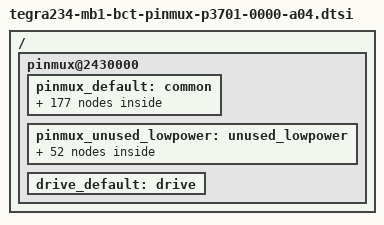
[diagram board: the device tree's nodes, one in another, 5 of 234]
/*This dtsi file was generated by jetson_agx_orin.xlsm Revision: 2 */
/*
 * SPDX-FileCopyrightText: Copyright (c) 2022-2024 NVIDIA CORPORATION & AFFILIATES. All rights reserved.
 * SPDX-License-Identifier: BSD-3-Clause
 *
 * Redistribution and use in source and binary forms, with or without
 * modification, are permitted provided that the following conditions are met:
 *
 * 1. Redistributions of source code must retain the above copyright notice, this
 * list of conditions and the following disclaimer.
 *
 * 2. Redistributions in binary form must reproduce the above copyright notice,
 * this list of conditions and the following disclaimer in the documentation
 * and/or other materials provided with the distribution.
 *
 * 3. Neither the name of the copyright holder nor the names of its
 * contributors may be used to endorse or promote products derived from
 * this software without specific prior written permission.
 *
 * THIS SOFTWARE IS PROVIDED BY THE COPYRIGHT HOLDERS AND CONTRIBUTORS 'AS IS'
 * AND ANY EXPRESS OR IMPLIED WARRANTIES, INCLUDING, BUT NOT LIMITED TO, THE
 * IMPLIED WARRANTIES OF MERCHANTABILITY AND FITNESS FOR A PARTICULAR PURPOSE ARE
 * DISCLAIMED. IN NO EVENT SHALL THE COPYRIGHT HOLDER OR CONTRIBUTORS BE LIABLE
 * FOR ANY DIRECT, INDIRECT, INCIDENTAL, SPECIAL, EXEMPLARY, OR CONSEQUENTIAL
 * DAMAGES (INCLUDING, BUT NOT LIMITED TO, PROCUREMENT OF SUBSTITUTE GOODS OR
 * SERVICES; LOSS OF USE, DATA, OR PROFITS; OR BUSINESS INTERRUPTION) HOWEVER
 * CAUSED AND ON ANY THEORY OF LIABILITY, WHETHER IN CONTRACT, STRICT LIABILITY,
 * OR TORT (INCLUDING NEGLIGENCE OR OTHERWISE) ARISING IN ANY WAY OUT OF THE USE
 * OF THIS SOFTWARE, EVEN IF ADVISED OF THE POSSIBILITY OF SUCH DAMAGE.
 */

/dts-v1/;
#include "pinctrl-tegra.h"
#include "tegra234-mb1-bct-gpio-p3701-0000-a04.dtsi"

/ {
	pinmux@2430000 {
		pinctrl-names = "default", "drive", "unused";
		pinctrl-0 = <&pinmux_default>;
		pinctrl-1 = <&drive_default>;
		pinctrl-2 = <&pinmux_unused_lowpower>;

		pinmux_default: common {
			/* SFIO Pin Configuration */
			shutdown_n {
				nvidia,pins = "shutdown_n";
				nvidia,function = "shutdown";
				nvidia,pull = <TEGRA_PIN_PULL_NONE>;
				nvidia,tristate = <TEGRA_PIN_DISABLE>;
				nvidia,enable-input = <TEGRA_PIN_DISABLE>;
				nvidia,io-high-voltage = <TEGRA_PIN_DISABLE>;
				nvidia,lpdr = <TEGRA_PIN_DISABLE>;
			};

			batt_oc_pee3 {
				nvidia,pins = "batt_oc_pee3";
				nvidia,function = "soc";
				nvidia,pull = <TEGRA_PIN_PULL_NONE>;
				nvidia,tristate = <TEGRA_PIN_ENABLE>;
				nvidia,enable-input = <TEGRA_PIN_ENABLE>;
				nvidia,io-high-voltage = <TEGRA_PIN_DISABLE>;
				nvidia,lpdr = <TEGRA_PIN_DISABLE>;
			};

			hdmi_cec_pgg0 {
				nvidia,pins = "hdmi_cec_pgg0";
				nvidia,function = "hdmi";
				nvidia,pull = <TEGRA_PIN_PULL_NONE>;
				nvidia,tristate = <TEGRA_PIN_DISABLE>;
				nvidia,enable-input = <TEGRA_PIN_ENABLE>;
				nvidia,io-high-voltage = <TEGRA_PIN_ENABLE>;
				nvidia,lpdr = <TEGRA_PIN_DISABLE>;
			};

			touch_clk_pcc4 {
				nvidia,pins = "touch_clk_pcc4";
				nvidia,function = "gp";
				nvidia,pull = <TEGRA_PIN_PULL_NONE>;
				nvidia,tristate = <TEGRA_PIN_ENABLE>;
				nvidia,enable-input = <TEGRA_PIN_DISABLE>;
				nvidia,io-high-voltage = <TEGRA_PIN_ENABLE>;
				nvidia,lpdr = <TEGRA_PIN_DISABLE>;
			};

			uart3_tx_pcc5 {
				nvidia,pins = "uart3_tx_pcc5";
				nvidia,function = "uartc";
				nvidia,pull = <TEGRA_PIN_PULL_NONE>;
				nvidia,tristate = <TEGRA_PIN_DISABLE>;
				nvidia,enable-input = <TEGRA_PIN_DISABLE>;
				nvidia,io-high-voltage = <TEGRA_PIN_DISABLE>;
				nvidia,lpdr = <TEGRA_PIN_DISABLE>;
			};

			uart3_rx_pcc6 {
				nvidia,pins = "uart3_rx_pcc6";
				nvidia,function = "uartc";
				nvidia,pull = <TEGRA_PIN_PULL_NONE>;
				nvidia,tristate = <TEGRA_PIN_ENABLE>;
				nvidia,enable-input = <TEGRA_PIN_ENABLE>;
				nvidia,io-high-voltage = <TEGRA_PIN_DISABLE>;
				nvidia,lpdr = <TEGRA_PIN_DISABLE>;
			};

			gen2_i2c_scl_pcc7 {
				nvidia,pins = "gen2_i2c_scl_pcc7";
				nvidia,function = "i2c2";
				nvidia,pull = <TEGRA_PIN_PULL_NONE>;
				nvidia,tristate = <TEGRA_PIN_DISABLE>;
				nvidia,enable-input = <TEGRA_PIN_ENABLE>;
				nvidia,io-high-voltage = <TEGRA_PIN_ENABLE>;
				nvidia,lpdr = <TEGRA_PIN_DISABLE>;
			};

			gen2_i2c_sda_pdd0 {
				nvidia,pins = "gen2_i2c_sda_pdd0";
				nvidia,function = "i2c2";
				nvidia,pull = <TEGRA_PIN_PULL_NONE>;
				nvidia,tristate = <TEGRA_PIN_DISABLE>;
				nvidia,enable-input = <TEGRA_PIN_ENABLE>;
				nvidia,io-high-voltage = <TEGRA_PIN_ENABLE>;
				nvidia,lpdr = <TEGRA_PIN_DISABLE>;
			};

			gen8_i2c_scl_pdd1 {
				nvidia,pins = "gen8_i2c_scl_pdd1";
				nvidia,function = "i2c8";
				nvidia,pull = <TEGRA_PIN_PULL_NONE>;
				nvidia,tristate = <TEGRA_PIN_DISABLE>;
				nvidia,enable-input = <TEGRA_PIN_ENABLE>;
				nvidia,io-high-voltage = <TEGRA_PIN_ENABLE>;
				nvidia,lpdr = <TEGRA_PIN_DISABLE>;
			};

			gen8_i2c_sda_pdd2 {
				nvidia,pins = "gen8_i2c_sda_pdd2";
				nvidia,function = "i2c8";
				nvidia,pull = <TEGRA_PIN_PULL_NONE>;
				nvidia,tristate = <TEGRA_PIN_DISABLE>;
				nvidia,enable-input = <TEGRA_PIN_ENABLE>;
				nvidia,io-high-voltage = <TEGRA_PIN_ENABLE>;
				nvidia,lpdr = <TEGRA_PIN_DISABLE>;
			};

			can0_stb_paa4 {
				nvidia,pins = "can0_stb_paa4";
				nvidia,function = "tsc_edge_out2";
				nvidia,pull = <TEGRA_PIN_PULL_DOWN>;
				nvidia,tristate = <TEGRA_PIN_DISABLE>;
				nvidia,enable-input = <TEGRA_PIN_DISABLE>;
			};

			can0_err_paa7 {
				nvidia,pins = "can0_err_paa7";
				nvidia,function = "tsc_edge_out3";
				nvidia,pull = <TEGRA_PIN_PULL_DOWN>;
				nvidia,tristate = <TEGRA_PIN_DISABLE>;
				nvidia,enable-input = <TEGRA_PIN_DISABLE>;
			};

			soc_gpio50_pbb2 {
				nvidia,pins = "soc_gpio50_pbb2";
				nvidia,function = "tsc_edge_out0";
				nvidia,pull = <TEGRA_PIN_PULL_DOWN>;
				nvidia,tristate = <TEGRA_PIN_DISABLE>;
				nvidia,enable-input = <TEGRA_PIN_DISABLE>;
			};

			gp_pwm2_px2 {
				nvidia,pins = "gp_pwm2_px2";
				nvidia,function = "gp";
				nvidia,pull = <TEGRA_PIN_PULL_NONE>;
				nvidia,tristate = <TEGRA_PIN_ENABLE>;
				nvidia,enable-input = <TEGRA_PIN_DISABLE>;
				nvidia,io-high-voltage = <TEGRA_PIN_ENABLE>;
				nvidia,lpdr = <TEGRA_PIN_DISABLE>;
			};

			gp_pwm3_px3 {
				nvidia,pins = "gp_pwm3_px3";
				nvidia,function = "gp";
				nvidia,pull = <TEGRA_PIN_PULL_NONE>;
				nvidia,tristate = <TEGRA_PIN_DISABLE>;
				nvidia,enable-input = <TEGRA_PIN_DISABLE>;
				nvidia,io-high-voltage = <TEGRA_PIN_DISABLE>;
				nvidia,lpdr = <TEGRA_PIN_DISABLE>;
			};

			uart2_tx_px4 {
				nvidia,pins = "uart2_tx_px4";
				nvidia,function = "uartb";
				nvidia,pull = <TEGRA_PIN_PULL_NONE>;
				nvidia,tristate = <TEGRA_PIN_DISABLE>;
				nvidia,enable-input = <TEGRA_PIN_DISABLE>;
				nvidia,io-high-voltage = <TEGRA_PIN_DISABLE>;
				nvidia,lpdr = <TEGRA_PIN_DISABLE>;
			};

			uart2_rx_px5 {
				nvidia,pins = "uart2_rx_px5";
				nvidia,function = "uartb";
				nvidia,pull = <TEGRA_PIN_PULL_NONE>;
				nvidia,tristate = <TEGRA_PIN_ENABLE>;
				nvidia,enable-input = <TEGRA_PIN_ENABLE>;
				nvidia,io-high-voltage = <TEGRA_PIN_DISABLE>;
				nvidia,lpdr = <TEGRA_PIN_DISABLE>;
			};

			uart2_rts_px6 {
				nvidia,pins = "uart2_rts_px6";
				nvidia,function = "uartb";
				nvidia,pull = <TEGRA_PIN_PULL_NONE>;
				nvidia,tristate = <TEGRA_PIN_DISABLE>;
				nvidia,enable-input = <TEGRA_PIN_DISABLE>;
				nvidia,lpdr = <TEGRA_PIN_DISABLE>;
			};

			uart2_cts_px7 {
				nvidia,pins = "uart2_cts_px7";
				nvidia,function = "uartb";
				nvidia,pull = <TEGRA_PIN_PULL_NONE>;
				nvidia,tristate = <TEGRA_PIN_ENABLE>;
				nvidia,enable-input = <TEGRA_PIN_ENABLE>;
				nvidia,lpdr = <TEGRA_PIN_DISABLE>;
			};

			uart5_tx_py5 {
				nvidia,pins = "uart5_tx_py5";
				nvidia,function = "uarti";
				nvidia,pull = <TEGRA_PIN_PULL_NONE>;
				nvidia,tristate = <TEGRA_PIN_DISABLE>;
				nvidia,enable-input = <TEGRA_PIN_DISABLE>;
				nvidia,lpdr = <TEGRA_PIN_DISABLE>;
			};

			uart5_rx_py6 {
				nvidia,pins = "uart5_rx_py6";
				nvidia,function = "uarti";
				nvidia,pull = <TEGRA_PIN_PULL_NONE>;
				nvidia,tristate = <TEGRA_PIN_ENABLE>;
				nvidia,enable-input = <TEGRA_PIN_ENABLE>;
				nvidia,lpdr = <TEGRA_PIN_DISABLE>;
			};

			extperiph1_clk_pp0 {
				nvidia,pins = "extperiph1_clk_pp0";
				nvidia,function = "extperiph1";
				nvidia,pull = <TEGRA_PIN_PULL_NONE>;
				nvidia,tristate = <TEGRA_PIN_DISABLE>;
				nvidia,enable-input = <TEGRA_PIN_DISABLE>;
				nvidia,lpdr = <TEGRA_PIN_DISABLE>;
			};

			extperiph2_clk_pp1 {
				nvidia,pins = "extperiph2_clk_pp1";
				nvidia,function = "extperiph2";
				nvidia,pull = <TEGRA_PIN_PULL_NONE>;
				nvidia,tristate = <TEGRA_PIN_DISABLE>;
				nvidia,enable-input = <TEGRA_PIN_DISABLE>;
				nvidia,lpdr = <TEGRA_PIN_DISABLE>;
			};

			cam_i2c_scl_pp2 {
				nvidia,pins = "cam_i2c_scl_pp2";
				nvidia,function = "i2c3";
				nvidia,pull = <TEGRA_PIN_PULL_NONE>;
				nvidia,tristate = <TEGRA_PIN_DISABLE>;
				nvidia,enable-input = <TEGRA_PIN_ENABLE>;
				nvidia,io-high-voltage = <TEGRA_PIN_ENABLE>;
				nvidia,lpdr = <TEGRA_PIN_DISABLE>;
			};

			cam_i2c_sda_pp3 {
				nvidia,pins = "cam_i2c_sda_pp3";
				nvidia,function = "i2c3";
				nvidia,pull = <TEGRA_PIN_PULL_NONE>;
				nvidia,tristate = <TEGRA_PIN_DISABLE>;
				nvidia,enable-input = <TEGRA_PIN_ENABLE>;
				nvidia,io-high-voltage = <TEGRA_PIN_ENABLE>;
				nvidia,lpdr = <TEGRA_PIN_DISABLE>;
			};

			soc_gpio24_pp5 {
				nvidia,pins = "soc_gpio24_pp5";
				nvidia,function = "soc";
				nvidia,pull = <TEGRA_PIN_PULL_NONE>;
				nvidia,tristate = <TEGRA_PIN_ENABLE>;
				nvidia,enable-input = <TEGRA_PIN_ENABLE>;
				nvidia,io-high-voltage = <TEGRA_PIN_DISABLE>;
				nvidia,lpdr = <TEGRA_PIN_DISABLE>;
			};

			pwr_i2c_scl_pp7 {
				nvidia,pins = "pwr_i2c_scl_pp7";
				nvidia,function = "i2c5";
				nvidia,pull = <TEGRA_PIN_PULL_NONE>;
				nvidia,tristate = <TEGRA_PIN_DISABLE>;
				nvidia,enable-input = <TEGRA_PIN_ENABLE>;
				nvidia,io-high-voltage = <TEGRA_PIN_DISABLE>;
				nvidia,lpdr = <TEGRA_PIN_DISABLE>;
			};

			pwr_i2c_sda_pq0 {
				nvidia,pins = "pwr_i2c_sda_pq0";
				nvidia,function = "i2c5";
				nvidia,pull = <TEGRA_PIN_PULL_NONE>;
				nvidia,tristate = <TEGRA_PIN_DISABLE>;
				nvidia,enable-input = <TEGRA_PIN_ENABLE>;
				nvidia,io-high-voltage = <TEGRA_PIN_DISABLE>;
				nvidia,lpdr = <TEGRA_PIN_DISABLE>;
			};

			soc_gpio29_pq2 {
				nvidia,pins = "soc_gpio29_pq2";
				nvidia,function = "nv";
				nvidia,pull = <TEGRA_PIN_PULL_NONE>;
				nvidia,tristate = <TEGRA_PIN_ENABLE>;
				nvidia,enable-input = <TEGRA_PIN_ENABLE>;
				nvidia,io-high-voltage = <TEGRA_PIN_DISABLE>;
				nvidia,lpdr = <TEGRA_PIN_DISABLE>;
			};

			soc_gpio32_pq5 {
				nvidia,pins = "soc_gpio32_pq5";
				nvidia,function = "extperiph3";
				nvidia,pull = <TEGRA_PIN_PULL_DOWN>;
				nvidia,tristate = <TEGRA_PIN_DISABLE>;
				nvidia,enable-input = <TEGRA_PIN_DISABLE>;
				nvidia,io-high-voltage = <TEGRA_PIN_DISABLE>;
				nvidia,lpdr = <TEGRA_PIN_DISABLE>;
			};

			soc_gpio37_pr0 {
				nvidia,pins = "soc_gpio37_pr0";
				nvidia,function = "gp";
				nvidia,pull = <TEGRA_PIN_PULL_NONE>;
				nvidia,tristate = <TEGRA_PIN_DISABLE>;
				nvidia,enable-input = <TEGRA_PIN_DISABLE>;
				nvidia,io-high-voltage = <TEGRA_PIN_DISABLE>;
				nvidia,lpdr = <TEGRA_PIN_DISABLE>;
			};

			uart1_tx_pr2 {
				nvidia,pins = "uart1_tx_pr2";
				nvidia,function = "uarta";
				nvidia,pull = <TEGRA_PIN_PULL_NONE>;
				nvidia,tristate = <TEGRA_PIN_DISABLE>;
				nvidia,enable-input = <TEGRA_PIN_DISABLE>;
				nvidia,lpdr = <TEGRA_PIN_DISABLE>;
			};

			uart1_rx_pr3 {
				nvidia,pins = "uart1_rx_pr3";
				nvidia,function = "uarta";
				nvidia,pull = <TEGRA_PIN_PULL_UP>;
				nvidia,tristate = <TEGRA_PIN_ENABLE>;
				nvidia,enable-input = <TEGRA_PIN_ENABLE>;
				nvidia,lpdr = <TEGRA_PIN_DISABLE>;
			};

			uart1_rts_pr4 {
				nvidia,pins = "uart1_rts_pr4";
				nvidia,function = "uarta";
				nvidia,pull = <TEGRA_PIN_PULL_NONE>;
				nvidia,tristate = <TEGRA_PIN_DISABLE>;
				nvidia,enable-input = <TEGRA_PIN_DISABLE>;
				nvidia,lpdr = <TEGRA_PIN_DISABLE>;
			};

			uart1_cts_pr5 {
				nvidia,pins = "uart1_cts_pr5";
				nvidia,function = "uarta";
				nvidia,pull = <TEGRA_PIN_PULL_UP>;
				nvidia,tristate = <TEGRA_PIN_ENABLE>;
				nvidia,enable-input = <TEGRA_PIN_ENABLE>;
				nvidia,lpdr = <TEGRA_PIN_DISABLE>;
			};

			dp_aux_ch0_hpd_pm0 {
				nvidia,pins = "dp_aux_ch0_hpd_pm0";
				nvidia,function = "dp";
				nvidia,pull = <TEGRA_PIN_PULL_NONE>;
				nvidia,tristate = <TEGRA_PIN_ENABLE>;
				nvidia,enable-input = <TEGRA_PIN_ENABLE>;
				nvidia,io-high-voltage = <TEGRA_PIN_DISABLE>;
				nvidia,lpdr = <TEGRA_PIN_DISABLE>;
			};

			dp_aux_ch1_hpd_pm1 {
				nvidia,pins = "dp_aux_ch1_hpd_pm1";
				nvidia,function = "eth3";
				nvidia,pull = <TEGRA_PIN_PULL_UP>;
				nvidia,tristate = <TEGRA_PIN_DISABLE>;
				nvidia,enable-input = <TEGRA_PIN_ENABLE>;
				nvidia,io-high-voltage = <TEGRA_PIN_DISABLE>;
				nvidia,lpdr = <TEGRA_PIN_DISABLE>;
			};

			dp_aux_ch2_hpd_pm2 {
				nvidia,pins = "dp_aux_ch2_hpd_pm2";
				nvidia,function = "eth3";
				nvidia,pull = <TEGRA_PIN_PULL_NONE>;
				nvidia,tristate = <TEGRA_PIN_DISABLE>;
				nvidia,enable-input = <TEGRA_PIN_DISABLE>;
				nvidia,io-high-voltage = <TEGRA_PIN_DISABLE>;
				nvidia,lpdr = <TEGRA_PIN_DISABLE>;
			};

			dp_aux_ch3_p_pn7 {
				nvidia,pins = "dp_aux_ch3_p_pn7";
				nvidia,function = "i2c9";
				nvidia,pull = <TEGRA_PIN_PULL_NONE>;
				nvidia,tristate = <TEGRA_PIN_DISABLE>;
				nvidia,enable-input = <TEGRA_PIN_ENABLE>;
				nvidia,io-high-voltage = <TEGRA_PIN_ENABLE>;
				nvidia,lpdr = <TEGRA_PIN_DISABLE>;
			};

			dp_aux_ch3_n_pn0 {
				nvidia,pins = "dp_aux_ch3_n_pn0";
				nvidia,function = "i2c9";
				nvidia,pull = <TEGRA_PIN_PULL_NONE>;
				nvidia,tristate = <TEGRA_PIN_DISABLE>;
				nvidia,enable-input = <TEGRA_PIN_ENABLE>;
				nvidia,io-high-voltage = <TEGRA_PIN_ENABLE>;
				nvidia,lpdr = <TEGRA_PIN_DISABLE>;
			};

			dp_aux_ch3_hpd_pm3 {
				nvidia,pins = "dp_aux_ch3_hpd_pm3";
				nvidia,function = "eth2";
				nvidia,pull = <TEGRA_PIN_PULL_NONE>;
				nvidia,tristate = <TEGRA_PIN_DISABLE>;
				nvidia,enable-input = <TEGRA_PIN_ENABLE>;
				nvidia,io-high-voltage = <TEGRA_PIN_DISABLE>;
				nvidia,lpdr = <TEGRA_PIN_DISABLE>;
			};

			soc_gpio55_pm4 {
				nvidia,pins = "soc_gpio55_pm4";
				nvidia,function = "eth2";
				nvidia,pull = <TEGRA_PIN_PULL_NONE>;
				nvidia,tristate = <TEGRA_PIN_DISABLE>;
				nvidia,enable-input = <TEGRA_PIN_DISABLE>;
				nvidia,lpdr = <TEGRA_PIN_DISABLE>;
			};

			soc_gpio36_pm5 {
				nvidia,pins = "soc_gpio36_pm5";
				nvidia,function = "eth0";
				nvidia,pull = <TEGRA_PIN_PULL_NONE>;
				nvidia,tristate = <TEGRA_PIN_DISABLE>;
				nvidia,enable-input = <TEGRA_PIN_ENABLE>;
				nvidia,lpdr = <TEGRA_PIN_DISABLE>;
			};

			soc_gpio53_pm6 {
				nvidia,pins = "soc_gpio53_pm6";
				nvidia,function = "eth0";
				nvidia,pull = <TEGRA_PIN_PULL_NONE>;
				nvidia,tristate = <TEGRA_PIN_DISABLE>;
				nvidia,enable-input = <TEGRA_PIN_DISABLE>;
				nvidia,lpdr = <TEGRA_PIN_DISABLE>;
			};

			soc_gpio38_pm7 {
				nvidia,pins = "soc_gpio38_pm7";
				nvidia,function = "eth1";
				nvidia,pull = <TEGRA_PIN_PULL_NONE>;
				nvidia,tristate = <TEGRA_PIN_DISABLE>;
				nvidia,enable-input = <TEGRA_PIN_ENABLE>;
				nvidia,lpdr = <TEGRA_PIN_DISABLE>;
			};

			soc_gpio40_pn2 {
				nvidia,pins = "soc_gpio40_pn2";
				nvidia,function = "eth1";
				nvidia,pull = <TEGRA_PIN_PULL_NONE>;
				nvidia,tristate = <TEGRA_PIN_DISABLE>;
				nvidia,enable-input = <TEGRA_PIN_DISABLE>;
				nvidia,lpdr = <TEGRA_PIN_DISABLE>;
			};

			soc_gpio19_pg6 {
				nvidia,pins = "soc_gpio19_pg6";
				nvidia,function = "gp";
				nvidia,pull = <TEGRA_PIN_PULL_NONE>;
				nvidia,tristate = <TEGRA_PIN_ENABLE>;
				nvidia,enable-input = <TEGRA_PIN_DISABLE>;
				nvidia,lpdr = <TEGRA_PIN_DISABLE>;
			};

			gen1_i2c_scl_pi3 {
				nvidia,pins = "gen1_i2c_scl_pi3";
				nvidia,function = "i2c1";
				nvidia,pull = <TEGRA_PIN_PULL_NONE>;
				nvidia,tristate = <TEGRA_PIN_DISABLE>;
				nvidia,enable-input = <TEGRA_PIN_ENABLE>;
				nvidia,io-high-voltage = <TEGRA_PIN_ENABLE>;
				nvidia,lpdr = <TEGRA_PIN_DISABLE>;
			};

			gen1_i2c_sda_pi4 {
				nvidia,pins = "gen1_i2c_sda_pi4";
				nvidia,function = "i2c1";
				nvidia,pull = <TEGRA_PIN_PULL_NONE>;
				nvidia,tristate = <TEGRA_PIN_DISABLE>;
				nvidia,enable-input = <TEGRA_PIN_ENABLE>;
				nvidia,io-high-voltage = <TEGRA_PIN_ENABLE>;
				nvidia,lpdr = <TEGRA_PIN_DISABLE>;
			};

			soc_gpio07_pi6 {
				nvidia,pins = "soc_gpio07_pi6";
				nvidia,function = "gp";
				nvidia,pull = <TEGRA_PIN_PULL_NONE>;
				nvidia,tristate = <TEGRA_PIN_ENABLE>;
				nvidia,enable-input = <TEGRA_PIN_DISABLE>;
				nvidia,lpdr = <TEGRA_PIN_DISABLE>;
			};

			sdmmc1_clk_pj0 {
				nvidia,pins = "sdmmc1_clk_pj0";
				nvidia,function = "sdmmc1";
				nvidia,pull = <TEGRA_PIN_PULL_NONE>;
				nvidia,tristate = <TEGRA_PIN_DISABLE>;
				nvidia,enable-input = <TEGRA_PIN_ENABLE>;
				nvidia,loopback = <TEGRA_PIN_ENABLE>;
			};

			sdmmc1_cmd_pj1 {
				nvidia,pins = "sdmmc1_cmd_pj1";
				nvidia,function = "sdmmc1";
				nvidia,pull = <TEGRA_PIN_PULL_UP>;
				nvidia,tristate = <TEGRA_PIN_DISABLE>;
				nvidia,enable-input = <TEGRA_PIN_ENABLE>;
			};

			sdmmc1_dat0_pj2 {
				nvidia,pins = "sdmmc1_dat0_pj2";
				nvidia,function = "sdmmc1";
				nvidia,pull = <TEGRA_PIN_PULL_UP>;
				nvidia,tristate = <TEGRA_PIN_DISABLE>;
				nvidia,enable-input = <TEGRA_PIN_ENABLE>;
			};

			sdmmc1_dat1_pj3 {
				nvidia,pins = "sdmmc1_dat1_pj3";
				nvidia,function = "sdmmc1";
				nvidia,pull = <TEGRA_PIN_PULL_UP>;
				nvidia,tristate = <TEGRA_PIN_DISABLE>;
				nvidia,enable-input = <TEGRA_PIN_ENABLE>;
			};

			sdmmc1_dat2_pj4 {
				nvidia,pins = "sdmmc1_dat2_pj4";
				nvidia,function = "sdmmc1";
				nvidia,pull = <TEGRA_PIN_PULL_UP>;
				nvidia,tristate = <TEGRA_PIN_DISABLE>;
				nvidia,enable-input = <TEGRA_PIN_ENABLE>;
			};

			sdmmc1_dat3_pj5 {
				nvidia,pins = "sdmmc1_dat3_pj5";
				nvidia,function = "sdmmc1";
				nvidia,pull = <TEGRA_PIN_PULL_UP>;
				nvidia,tristate = <TEGRA_PIN_DISABLE>;
				nvidia,enable-input = <TEGRA_PIN_ENABLE>;
			};

			qspi0_sck_pc0 {
				nvidia,pins = "qspi0_sck_pc0";
				nvidia,function = "qspi0";
				nvidia,pull = <TEGRA_PIN_PULL_DOWN>;
				nvidia,tristate = <TEGRA_PIN_DISABLE>;
				nvidia,enable-input = <TEGRA_PIN_ENABLE>;
				nvidia,loopback = <TEGRA_PIN_ENABLE>;
			};

			qspi0_cs_n_pc1 {
				nvidia,pins = "qspi0_cs_n_pc1";
				nvidia,function = "qspi0";
				nvidia,pull = <TEGRA_PIN_PULL_UP>;
				nvidia,tristate = <TEGRA_PIN_DISABLE>;
				nvidia,enable-input = <TEGRA_PIN_DISABLE>;
			};

			qspi0_io0_pc2 {
				nvidia,pins = "qspi0_io0_pc2";
				nvidia,function = "qspi0";
				nvidia,pull = <TEGRA_PIN_PULL_UP>;
				nvidia,tristate = <TEGRA_PIN_DISABLE>;
				nvidia,enable-input = <TEGRA_PIN_ENABLE>;
			};

			qspi0_io1_pc3 {
				nvidia,pins = "qspi0_io1_pc3";
				nvidia,function = "qspi0";
				nvidia,pull = <TEGRA_PIN_PULL_UP>;
				nvidia,tristate = <TEGRA_PIN_DISABLE>;
				nvidia,enable-input = <TEGRA_PIN_ENABLE>;
			};

			qspi0_io2_pc4 {
				nvidia,pins = "qspi0_io2_pc4";
				nvidia,function = "qspi0";
				nvidia,pull = <TEGRA_PIN_PULL_UP>;
				nvidia,tristate = <TEGRA_PIN_DISABLE>;
				nvidia,enable-input = <TEGRA_PIN_ENABLE>;
			};

			qspi0_io3_pc5 {
				nvidia,pins = "qspi0_io3_pc5";
				nvidia,function = "qspi0";
				nvidia,pull = <TEGRA_PIN_PULL_UP>;
				nvidia,tristate = <TEGRA_PIN_DISABLE>;
				nvidia,enable-input = <TEGRA_PIN_ENABLE>;
			};

			soc_gpio59_pac6 {
				nvidia,pins = "soc_gpio59_pac6";
				nvidia,function = "aud";
				nvidia,pull = <TEGRA_PIN_PULL_NONE>;
				nvidia,tristate = <TEGRA_PIN_DISABLE>;
				nvidia,enable-input = <TEGRA_PIN_DISABLE>;
				nvidia,lpdr = <TEGRA_PIN_DISABLE>;
			};

			soc_gpio45_pad0 {
				nvidia,pins = "soc_gpio45_pad0";
				nvidia,function = "i2s1";
				nvidia,pull = <TEGRA_PIN_PULL_NONE>;
				nvidia,tristate = <TEGRA_PIN_DISABLE>;
				nvidia,enable-input = <TEGRA_PIN_ENABLE>;
				nvidia,lpdr = <TEGRA_PIN_DISABLE>;
			};

			soc_gpio46_pad1 {
				nvidia,pins = "soc_gpio46_pad1";
				nvidia,function = "i2s1";
				nvidia,pull = <TEGRA_PIN_PULL_NONE>;
				nvidia,tristate = <TEGRA_PIN_DISABLE>;
				nvidia,enable-input = <TEGRA_PIN_DISABLE>;
				nvidia,lpdr = <TEGRA_PIN_DISABLE>;
			};

			soc_gpio47_pad2 {
				nvidia,pins = "soc_gpio47_pad2";
				nvidia,function = "i2s1";
				nvidia,pull = <TEGRA_PIN_PULL_DOWN>;
				nvidia,tristate = <TEGRA_PIN_ENABLE>;
				nvidia,enable-input = <TEGRA_PIN_ENABLE>;
				nvidia,lpdr = <TEGRA_PIN_DISABLE>;
			};

			soc_gpio48_pad3 {
				nvidia,pins = "soc_gpio48_pad3";
				nvidia,function = "i2s1";
				nvidia,pull = <TEGRA_PIN_PULL_NONE>;
				nvidia,tristate = <TEGRA_PIN_DISABLE>;
				nvidia,enable-input = <TEGRA_PIN_ENABLE>;
				nvidia,lpdr = <TEGRA_PIN_DISABLE>;
			};

			pex_l1_clkreq_n_pk2 {
				nvidia,pins = "pex_l1_clkreq_n_pk2";
				nvidia,function = "pe1";
				nvidia,pull = <TEGRA_PIN_PULL_NONE>;
				nvidia,tristate = <TEGRA_PIN_DISABLE>;
				nvidia,enable-input = <TEGRA_PIN_ENABLE>;
				nvidia,io-high-voltage = <TEGRA_PIN_ENABLE>;
				nvidia,lpdr = <TEGRA_PIN_DISABLE>;
			};

			pex_l1_rst_n_pk3 {
				nvidia,pins = "pex_l1_rst_n_pk3";
				nvidia,function = "pe1";
				nvidia,pull = <TEGRA_PIN_PULL_NONE>;
				nvidia,tristate = <TEGRA_PIN_DISABLE>;
				nvidia,enable-input = <TEGRA_PIN_DISABLE>;
				nvidia,io-high-voltage = <TEGRA_PIN_ENABLE>;
				nvidia,lpdr = <TEGRA_PIN_DISABLE>;
			};

			pex_l4_clkreq_n_pl0 {
				nvidia,pins = "pex_l4_clkreq_n_pl0";
				nvidia,function = "pe4";
				nvidia,pull = <TEGRA_PIN_PULL_NONE>;
				nvidia,tristate = <TEGRA_PIN_DISABLE>;
				nvidia,enable-input = <TEGRA_PIN_ENABLE>;
				nvidia,io-high-voltage = <TEGRA_PIN_ENABLE>;
				nvidia,lpdr = <TEGRA_PIN_DISABLE>;
			};

			pex_l4_rst_n_pl1 {
				nvidia,pins = "pex_l4_rst_n_pl1";
				nvidia,function = "pe4";
				nvidia,pull = <TEGRA_PIN_PULL_NONE>;
				nvidia,tristate = <TEGRA_PIN_DISABLE>;
				nvidia,enable-input = <TEGRA_PIN_DISABLE>;
				nvidia,io-high-voltage = <TEGRA_PIN_ENABLE>;
				nvidia,lpdr = <TEGRA_PIN_DISABLE>;
			};

			dap4_sclk_pa4 {
				nvidia,pins = "dap4_sclk_pa4";
				nvidia,function = "i2s4";
				nvidia,pull = <TEGRA_PIN_PULL_NONE>;
				nvidia,tristate = <TEGRA_PIN_DISABLE>;
				nvidia,enable-input = <TEGRA_PIN_ENABLE>;
				nvidia,lpdr = <TEGRA_PIN_DISABLE>;
			};

			dap4_dout_pa5 {
				nvidia,pins = "dap4_dout_pa5";
				nvidia,function = "i2s4";
				nvidia,pull = <TEGRA_PIN_PULL_NONE>;
				nvidia,tristate = <TEGRA_PIN_DISABLE>;
				nvidia,enable-input = <TEGRA_PIN_DISABLE>;
				nvidia,lpdr = <TEGRA_PIN_DISABLE>;
			};

			dap4_din_pa6 {
				nvidia,pins = "dap4_din_pa6";
				nvidia,function = "i2s4";
				nvidia,pull = <TEGRA_PIN_PULL_DOWN>;
				nvidia,tristate = <TEGRA_PIN_ENABLE>;
				nvidia,enable-input = <TEGRA_PIN_ENABLE>;
				nvidia,lpdr = <TEGRA_PIN_DISABLE>;
			};

			dap4_fs_pa7 {
				nvidia,pins = "dap4_fs_pa7";
				nvidia,function = "i2s4";
				nvidia,pull = <TEGRA_PIN_PULL_NONE>;
				nvidia,tristate = <TEGRA_PIN_DISABLE>;
				nvidia,enable-input = <TEGRA_PIN_ENABLE>;
				nvidia,lpdr = <TEGRA_PIN_DISABLE>;
			};

			pex_l5_clkreq_n_paf0 {
				nvidia,pins = "pex_l5_clkreq_n_paf0";
				nvidia,function = "pe5";
				nvidia,pull = <TEGRA_PIN_PULL_NONE>;
				nvidia,tristate = <TEGRA_PIN_DISABLE>;
				nvidia,enable-input = <TEGRA_PIN_ENABLE>;
				nvidia,io-high-voltage = <TEGRA_PIN_ENABLE>;
				nvidia,lpdr = <TEGRA_PIN_DISABLE>;
			};

			pex_l5_rst_n_paf1 {
				nvidia,pins = "pex_l5_rst_n_paf1";
				nvidia,function = "pe5";
				nvidia,pull = <TEGRA_PIN_PULL_NONE>;
				nvidia,tristate = <TEGRA_PIN_DISABLE>;
				nvidia,enable-input = <TEGRA_PIN_DISABLE>;
				nvidia,io-high-voltage = <TEGRA_PIN_ENABLE>;
				nvidia,lpdr = <TEGRA_PIN_DISABLE>;
			};

			emmc_clk {
				nvidia,pins = "emmc_clk";
				nvidia,function = "emmc";
				nvidia,pull = <TEGRA_PIN_PULL_NONE>;
				nvidia,tristate = <TEGRA_PIN_DISABLE>;
				nvidia,enable-input = <TEGRA_PIN_ENABLE>;
				nvidia,loopback = <TEGRA_PIN_ENABLE>;
			};

			emmc_cmd {
				nvidia,pins = "emmc_cmd";
				nvidia,function = "emmc";
				nvidia,pull = <TEGRA_PIN_PULL_NONE>;
				nvidia,tristate = <TEGRA_PIN_DISABLE>;
				nvidia,enable-input = <TEGRA_PIN_ENABLE>;
				nvidia,loopback = <TEGRA_PIN_DISABLE>;
			};

			emmc_dat0 {
				nvidia,pins = "emmc_dat0";
				nvidia,function = "emmc";
				nvidia,pull = <TEGRA_PIN_PULL_UP>;
				nvidia,tristate = <TEGRA_PIN_DISABLE>;
				nvidia,enable-input = <TEGRA_PIN_ENABLE>;
				nvidia,loopback = <TEGRA_PIN_DISABLE>;
			};

			emmc_dat1 {
				nvidia,pins = "emmc_dat1";
				nvidia,function = "emmc";
				nvidia,pull = <TEGRA_PIN_PULL_UP>;
				nvidia,tristate = <TEGRA_PIN_DISABLE>;
				nvidia,enable-input = <TEGRA_PIN_ENABLE>;
				nvidia,loopback = <TEGRA_PIN_DISABLE>;
			};

			emmc_dat2 {
				nvidia,pins = "emmc_dat2";
				nvidia,function = "emmc";
				nvidia,pull = <TEGRA_PIN_PULL_UP>;
				nvidia,tristate = <TEGRA_PIN_DISABLE>;
				nvidia,enable-input = <TEGRA_PIN_ENABLE>;
				nvidia,loopback = <TEGRA_PIN_DISABLE>;
			};

			emmc_dat3 {
				nvidia,pins = "emmc_dat3";
				nvidia,function = "emmc";
				nvidia,pull = <TEGRA_PIN_PULL_UP>;
				nvidia,tristate = <TEGRA_PIN_DISABLE>;
				nvidia,enable-input = <TEGRA_PIN_ENABLE>;
				nvidia,loopback = <TEGRA_PIN_DISABLE>;
			};

			emmc_dat4 {
				nvidia,pins = "emmc_dat4";
				nvidia,function = "emmc";
				nvidia,pull = <TEGRA_PIN_PULL_UP>;
				nvidia,tristate = <TEGRA_PIN_DISABLE>;
				nvidia,enable-input = <TEGRA_PIN_ENABLE>;
				nvidia,loopback = <TEGRA_PIN_DISABLE>;
			};

			emmc_dat5 {
				nvidia,pins = "emmc_dat5";
				nvidia,function = "emmc";
				nvidia,pull = <TEGRA_PIN_PULL_UP>;
				nvidia,tristate = <TEGRA_PIN_DISABLE>;
				nvidia,enable-input = <TEGRA_PIN_ENABLE>;
				nvidia,loopback = <TEGRA_PIN_DISABLE>;
			};

			emmc_dat6 {
				nvidia,pins = "emmc_dat6";
				nvidia,function = "emmc";
				nvidia,pull = <TEGRA_PIN_PULL_UP>;
				nvidia,tristate = <TEGRA_PIN_DISABLE>;
				nvidia,enable-input = <TEGRA_PIN_ENABLE>;
				nvidia,loopback = <TEGRA_PIN_DISABLE>;
			};

			emmc_dat7 {
				nvidia,pins = "emmc_dat7";
				nvidia,function = "emmc";
				nvidia,pull = <TEGRA_PIN_PULL_UP>;
				nvidia,tristate = <TEGRA_PIN_DISABLE>;
				nvidia,enable-input = <TEGRA_PIN_ENABLE>;
				nvidia,loopback = <TEGRA_PIN_DISABLE>;
			};

			emmc_dqs {
				nvidia,pins = "emmc_dqs";
				nvidia,function = "emmc";
				nvidia,pull = <TEGRA_PIN_PULL_NONE>;
				nvidia,tristate = <TEGRA_PIN_ENABLE>;
				nvidia,enable-input = <TEGRA_PIN_ENABLE>;
			};

			/* GPIO Pin Configuration */
			soc_gpio26_pee5 {
				nvidia,pins = "soc_gpio26_pee5";
				nvidia,function = "rsvd0";
				nvidia,pull = <TEGRA_PIN_PULL_NONE>;
				nvidia,tristate = <TEGRA_PIN_ENABLE>;
				nvidia,enable-input = <TEGRA_PIN_ENABLE>;
				nvidia,io-high-voltage = <TEGRA_PIN_DISABLE>;
				nvidia,lpdr = <TEGRA_PIN_DISABLE>;
			};

			soc_gpio27_pee6 {
				nvidia,pins = "soc_gpio27_pee6";
				nvidia,function = "rsvd0";
				nvidia,pull = <TEGRA_PIN_PULL_NONE>;
				nvidia,tristate = <TEGRA_PIN_ENABLE>;
				nvidia,enable-input = <TEGRA_PIN_ENABLE>;
				nvidia,io-high-voltage = <TEGRA_PIN_DISABLE>;
				nvidia,lpdr = <TEGRA_PIN_DISABLE>;
			};

			ao_retention_n_pee2 {
				nvidia,pins = "ao_retention_n_pee2";
				nvidia,function = "rsvd2";
				nvidia,pull = <TEGRA_PIN_PULL_NONE>;
				nvidia,tristate = <TEGRA_PIN_ENABLE>;
				nvidia,enable-input = <TEGRA_PIN_ENABLE>;
				nvidia,io-high-voltage = <TEGRA_PIN_DISABLE>;
				nvidia,lpdr = <TEGRA_PIN_DISABLE>;
			};

			power_on_pee4 {
				nvidia,pins = "power_on_pee4";
				nvidia,function = "rsvd0";
				nvidia,pull = <TEGRA_PIN_PULL_UP>;
				nvidia,tristate = <TEGRA_PIN_ENABLE>;
				nvidia,enable-input = <TEGRA_PIN_ENABLE>;
				nvidia,io-high-voltage = <TEGRA_PIN_DISABLE>;
				nvidia,lpdr = <TEGRA_PIN_DISABLE>;
			};

			spi2_sck_pcc0 {
				nvidia,pins = "spi2_sck_pcc0";
				nvidia,function = "rsvd1";
				nvidia,pull = <TEGRA_PIN_PULL_UP>;
				nvidia,tristate = <TEGRA_PIN_ENABLE>;
				nvidia,enable-input = <TEGRA_PIN_ENABLE>;
				nvidia,io-high-voltage = <TEGRA_PIN_DISABLE>;
				nvidia,lpdr = <TEGRA_PIN_DISABLE>;
			};

			spi2_miso_pcc1 {
				nvidia,pins = "spi2_miso_pcc1";
				nvidia,function = "rsvd1";
				nvidia,pull = <TEGRA_PIN_PULL_UP>;
				nvidia,tristate = <TEGRA_PIN_ENABLE>;
				nvidia,enable-input = <TEGRA_PIN_ENABLE>;
				nvidia,io-high-voltage = <TEGRA_PIN_DISABLE>;
				nvidia,lpdr = <TEGRA_PIN_DISABLE>;
			};

			spi2_mosi_pcc2 {
				nvidia,pins = "spi2_mosi_pcc2";
				nvidia,function = "rsvd1";
				nvidia,pull = <TEGRA_PIN_PULL_UP>;
				nvidia,tristate = <TEGRA_PIN_ENABLE>;
				nvidia,enable-input = <TEGRA_PIN_ENABLE>;
				nvidia,io-high-voltage = <TEGRA_PIN_DISABLE>;
				nvidia,lpdr = <TEGRA_PIN_DISABLE>;
			};

			spi2_cs0_pcc3 {
				nvidia,pins = "spi2_cs0_pcc3";
				nvidia,function = "rsvd1";
				nvidia,pull = <TEGRA_PIN_PULL_UP>;
				nvidia,tristate = <TEGRA_PIN_ENABLE>;
				nvidia,enable-input = <TEGRA_PIN_ENABLE>;
				nvidia,io-high-voltage = <TEGRA_PIN_DISABLE>;
				nvidia,lpdr = <TEGRA_PIN_DISABLE>;
			};

			can0_dout_paa0 {
				nvidia,pins = "can0_dout_paa0";
				nvidia,function = "rsvd1";
				nvidia,pull = <TEGRA_PIN_PULL_UP>;
				nvidia,tristate = <TEGRA_PIN_ENABLE>;
				nvidia,enable-input = <TEGRA_PIN_ENABLE>;
			};

			can0_din_paa1 {
				nvidia,pins = "can0_din_paa1";
				nvidia,function = "rsvd1";
				nvidia,pull = <TEGRA_PIN_PULL_DOWN>;
				nvidia,tristate = <TEGRA_PIN_ENABLE>;
				nvidia,enable-input = <TEGRA_PIN_ENABLE>;
			};

			can1_dout_paa2 {
				nvidia,pins = "can1_dout_paa2";
				nvidia,function = "rsvd1";
				nvidia,pull = <TEGRA_PIN_PULL_UP>;
				nvidia,tristate = <TEGRA_PIN_ENABLE>;
				nvidia,enable-input = <TEGRA_PIN_ENABLE>;
			};

			can1_din_paa3 {
				nvidia,pins = "can1_din_paa3";
				nvidia,function = "rsvd1";
				nvidia,pull = <TEGRA_PIN_PULL_DOWN>;
				nvidia,tristate = <TEGRA_PIN_ENABLE>;
				nvidia,enable-input = <TEGRA_PIN_ENABLE>;
			};

			can1_stb_pbb0 {
				nvidia,pins = "can1_stb_pbb0";
				nvidia,function = "rsvd0";
				nvidia,pull = <TEGRA_PIN_PULL_UP>;
				nvidia,tristate = <TEGRA_PIN_ENABLE>;
				nvidia,enable-input = <TEGRA_PIN_ENABLE>;
			};

			can1_en_pbb1 {
				nvidia,pins = "can1_en_pbb1";
				nvidia,function = "rsvd0";
				nvidia,pull = <TEGRA_PIN_PULL_DOWN>;
				nvidia,tristate = <TEGRA_PIN_ENABLE>;
				nvidia,enable-input = <TEGRA_PIN_ENABLE>;
			};

			can1_err_pbb3 {
				nvidia,pins = "can1_err_pbb3";
				nvidia,function = "rsvd0";
				nvidia,pull = <TEGRA_PIN_PULL_NONE>;
				nvidia,tristate = <TEGRA_PIN_DISABLE>;
				nvidia,enable-input = <TEGRA_PIN_DISABLE>;
			};

			soc_gpio08_pb0 {
				nvidia,pins = "soc_gpio08_pb0";
				nvidia,function = "rsvd0";
				nvidia,pull = <TEGRA_PIN_PULL_UP>;
				nvidia,tristate = <TEGRA_PIN_ENABLE>;
				nvidia,enable-input = <TEGRA_PIN_ENABLE>;
				nvidia,lpdr = <TEGRA_PIN_DISABLE>;
			};

			gpu_pwr_req_px0 {
				nvidia,pins = "gpu_pwr_req_px0";
				nvidia,function = "rsvd0";
				nvidia,pull = <TEGRA_PIN_PULL_NONE>;
				nvidia,tristate = <TEGRA_PIN_DISABLE>;
				nvidia,enable-input = <TEGRA_PIN_DISABLE>;
				nvidia,lpdr = <TEGRA_PIN_DISABLE>;
			};

			cv_pwr_req_px1 {
				nvidia,pins = "cv_pwr_req_px1";
				nvidia,function = "rsvd0";
				nvidia,pull = <TEGRA_PIN_PULL_NONE>;
				nvidia,tristate = <TEGRA_PIN_DISABLE>;
				nvidia,enable-input = <TEGRA_PIN_DISABLE>;
				nvidia,lpdr = <TEGRA_PIN_DISABLE>;
			};

			spi3_sck_py0 {
				nvidia,pins = "spi3_sck_py0";
				nvidia,function = "rsvd1";
				nvidia,pull = <TEGRA_PIN_PULL_NONE>;
				nvidia,tristate = <TEGRA_PIN_DISABLE>;
				nvidia,enable-input = <TEGRA_PIN_DISABLE>;
				nvidia,io-high-voltage = <TEGRA_PIN_DISABLE>;
				nvidia,lpdr = <TEGRA_PIN_DISABLE>;
			};

			spi3_miso_py1 {
				nvidia,pins = "spi3_miso_py1";
				nvidia,function = "rsvd1";
				nvidia,pull = <TEGRA_PIN_PULL_NONE>;
				nvidia,tristate = <TEGRA_PIN_DISABLE>;
				nvidia,enable-input = <TEGRA_PIN_DISABLE>;
				nvidia,io-high-voltage = <TEGRA_PIN_DISABLE>;
				nvidia,lpdr = <TEGRA_PIN_DISABLE>;
			};

			spi3_mosi_py2 {
				nvidia,pins = "spi3_mosi_py2";
				nvidia,function = "rsvd1";
				nvidia,pull = <TEGRA_PIN_PULL_NONE>;
				nvidia,tristate = <TEGRA_PIN_DISABLE>;
				nvidia,enable-input = <TEGRA_PIN_DISABLE>;
				nvidia,io-high-voltage = <TEGRA_PIN_DISABLE>;
				nvidia,lpdr = <TEGRA_PIN_DISABLE>;
			};

			spi3_cs0_py3 {
				nvidia,pins = "spi3_cs0_py3";
				nvidia,function = "rsvd1";
				nvidia,pull = <TEGRA_PIN_PULL_UP>;
				nvidia,tristate = <TEGRA_PIN_ENABLE>;
				nvidia,enable-input = <TEGRA_PIN_ENABLE>;
				nvidia,io-high-voltage = <TEGRA_PIN_DISABLE>;
				nvidia,lpdr = <TEGRA_PIN_DISABLE>;
			};

			spi3_cs1_py4 {
				nvidia,pins = "spi3_cs1_py4";
				nvidia,function = "rsvd1";
				nvidia,pull = <TEGRA_PIN_PULL_UP>;
				nvidia,tristate = <TEGRA_PIN_ENABLE>;
				nvidia,enable-input = <TEGRA_PIN_ENABLE>;
				nvidia,io-high-voltage = <TEGRA_PIN_DISABLE>;
				nvidia,lpdr = <TEGRA_PIN_DISABLE>;
			};

			uart5_rts_py7 {
				nvidia,pins = "uart5_rts_py7";
				nvidia,function = "rsvd1";
				nvidia,pull = <TEGRA_PIN_PULL_UP>;
				nvidia,tristate = <TEGRA_PIN_DISABLE>;
				nvidia,enable-input = <TEGRA_PIN_DISABLE>;
				nvidia,lpdr = <TEGRA_PIN_DISABLE>;
			};

			uart5_cts_pz0 {
				nvidia,pins = "uart5_cts_pz0";
				nvidia,function = "rsvd1";
				nvidia,pull = <TEGRA_PIN_PULL_NONE>;
				nvidia,tristate = <TEGRA_PIN_DISABLE>;
				nvidia,enable-input = <TEGRA_PIN_DISABLE>;
				nvidia,lpdr = <TEGRA_PIN_DISABLE>;
			};

			usb_vbus_en0_pz1 {
				nvidia,pins = "usb_vbus_en0_pz1";
				nvidia,function = "rsvd1";
				nvidia,pull = <TEGRA_PIN_PULL_UP>;
				nvidia,tristate = <TEGRA_PIN_ENABLE>;
				nvidia,enable-input = <TEGRA_PIN_ENABLE>;
				nvidia,io-high-voltage = <TEGRA_PIN_ENABLE>;
				nvidia,lpdr = <TEGRA_PIN_DISABLE>;
			};

			usb_vbus_en1_pz2 {
				nvidia,pins = "usb_vbus_en1_pz2";
				nvidia,function = "rsvd1";
				nvidia,pull = <TEGRA_PIN_PULL_DOWN>;
				nvidia,tristate = <TEGRA_PIN_ENABLE>;
				nvidia,enable-input = <TEGRA_PIN_ENABLE>;
				nvidia,io-high-voltage = <TEGRA_PIN_DISABLE>;
				nvidia,lpdr = <TEGRA_PIN_DISABLE>;
			};

			spi1_sck_pz3 {
				nvidia,pins = "spi1_sck_pz3";
				nvidia,function = "rsvd1";
				nvidia,pull = <TEGRA_PIN_PULL_DOWN>;
				nvidia,tristate = <TEGRA_PIN_ENABLE>;
				nvidia,enable-input = <TEGRA_PIN_ENABLE>;
				nvidia,io-high-voltage = <TEGRA_PIN_DISABLE>;
				nvidia,lpdr = <TEGRA_PIN_DISABLE>;
			};

			spi1_miso_pz4 {
				nvidia,pins = "spi1_miso_pz4";
				nvidia,function = "rsvd1";
				nvidia,pull = <TEGRA_PIN_PULL_DOWN>;
				nvidia,tristate = <TEGRA_PIN_ENABLE>;
				nvidia,enable-input = <TEGRA_PIN_ENABLE>;
				nvidia,io-high-voltage = <TEGRA_PIN_DISABLE>;
				nvidia,lpdr = <TEGRA_PIN_DISABLE>;
			};

			spi1_mosi_pz5 {
				nvidia,pins = "spi1_mosi_pz5";
				nvidia,function = "rsvd1";
				nvidia,pull = <TEGRA_PIN_PULL_DOWN>;
				nvidia,tristate = <TEGRA_PIN_ENABLE>;
				nvidia,enable-input = <TEGRA_PIN_ENABLE>;
				nvidia,io-high-voltage = <TEGRA_PIN_DISABLE>;
				nvidia,lpdr = <TEGRA_PIN_DISABLE>;
			};

			spi1_cs0_pz6 {
				nvidia,pins = "spi1_cs0_pz6";
				nvidia,function = "rsvd1";
				nvidia,pull = <TEGRA_PIN_PULL_DOWN>;
				nvidia,tristate = <TEGRA_PIN_ENABLE>;
				nvidia,enable-input = <TEGRA_PIN_ENABLE>;
				nvidia,io-high-voltage = <TEGRA_PIN_DISABLE>;
				nvidia,lpdr = <TEGRA_PIN_DISABLE>;
			};

			spi1_cs1_pz7 {
				nvidia,pins = "spi1_cs1_pz7";
				nvidia,function = "rsvd1";
				nvidia,pull = <TEGRA_PIN_PULL_DOWN>;
				nvidia,tristate = <TEGRA_PIN_ENABLE>;
				nvidia,enable-input = <TEGRA_PIN_ENABLE>;
				nvidia,io-high-voltage = <TEGRA_PIN_DISABLE>;
				nvidia,lpdr = <TEGRA_PIN_DISABLE>;
			};

			soc_gpio23_pp4 {
				nvidia,pins = "soc_gpio23_pp4";
				nvidia,function = "vi0";
				nvidia,pull = <TEGRA_PIN_PULL_DOWN>;
				nvidia,tristate = <TEGRA_PIN_ENABLE>;
				nvidia,enable-input = <TEGRA_PIN_ENABLE>;
				nvidia,io-high-voltage = <TEGRA_PIN_DISABLE>;
				nvidia,lpdr = <TEGRA_PIN_DISABLE>;
			};

			soc_gpio25_pp6 {
				nvidia,pins = "soc_gpio25_pp6";
				nvidia,function = "vi0";
				nvidia,pull = <TEGRA_PIN_PULL_DOWN>;
				nvidia,tristate = <TEGRA_PIN_ENABLE>;
				nvidia,enable-input = <TEGRA_PIN_ENABLE>;
				nvidia,io-high-voltage = <TEGRA_PIN_DISABLE>;
				nvidia,lpdr = <TEGRA_PIN_DISABLE>;
			};

			soc_gpio28_pq1 {
				nvidia,pins = "soc_gpio28_pq1";
				nvidia,function = "rsvd1";
				nvidia,pull = <TEGRA_PIN_PULL_NONE>;
				nvidia,tristate = <TEGRA_PIN_DISABLE>;
				nvidia,enable-input = <TEGRA_PIN_DISABLE>;
				nvidia,io-high-voltage = <TEGRA_PIN_DISABLE>;
				nvidia,lpdr = <TEGRA_PIN_DISABLE>;
			};

			soc_gpio31_pq4 {
				nvidia,pins = "soc_gpio31_pq4";
				nvidia,function = "rsvd0";
				nvidia,pull = <TEGRA_PIN_PULL_NONE>;
				nvidia,tristate = <TEGRA_PIN_DISABLE>;
				nvidia,enable-input = <TEGRA_PIN_DISABLE>;
				nvidia,io-high-voltage = <TEGRA_PIN_DISABLE>;
				nvidia,lpdr = <TEGRA_PIN_DISABLE>;
			};

			soc_gpio33_pq6 {
				nvidia,pins = "soc_gpio33_pq6";
				nvidia,function = "rsvd0";
				nvidia,pull = <TEGRA_PIN_PULL_DOWN>;
				nvidia,tristate = <TEGRA_PIN_ENABLE>;
				nvidia,enable-input = <TEGRA_PIN_ENABLE>;
				nvidia,io-high-voltage = <TEGRA_PIN_DISABLE>;
				nvidia,lpdr = <TEGRA_PIN_DISABLE>;
			};

			soc_gpio35_pq7 {
				nvidia,pins = "soc_gpio35_pq7";
				nvidia,function = "rsvd0";
				nvidia,pull = <TEGRA_PIN_PULL_UP>;
				nvidia,tristate = <TEGRA_PIN_ENABLE>;
				nvidia,enable-input = <TEGRA_PIN_ENABLE>;
				nvidia,io-high-voltage = <TEGRA_PIN_DISABLE>;
				nvidia,lpdr = <TEGRA_PIN_DISABLE>;
			};

			soc_gpio56_pr1 {
				nvidia,pins = "soc_gpio56_pr1";
				nvidia,function = "rsvd0";
				nvidia,pull = <TEGRA_PIN_PULL_UP>;
				nvidia,tristate = <TEGRA_PIN_ENABLE>;
				nvidia,enable-input = <TEGRA_PIN_ENABLE>;
				nvidia,io-high-voltage = <TEGRA_PIN_DISABLE>;
				nvidia,lpdr = <TEGRA_PIN_DISABLE>;
			};

			dp_aux_ch1_p_pn3 {
				nvidia,pins = "dp_aux_ch1_p_pn3";
				nvidia,function = "rsvd1";
				nvidia,pull = <TEGRA_PIN_PULL_NONE>;
				nvidia,tristate = <TEGRA_PIN_DISABLE>;
				nvidia,enable-input = <TEGRA_PIN_DISABLE>;
				nvidia,io-high-voltage = <TEGRA_PIN_ENABLE>;
				nvidia,lpdr = <TEGRA_PIN_DISABLE>;
			};

			dp_aux_ch1_n_pn4 {
				nvidia,pins = "dp_aux_ch1_n_pn4";
				nvidia,function = "rsvd1";
				nvidia,pull = <TEGRA_PIN_PULL_NONE>;
				nvidia,tristate = <TEGRA_PIN_ENABLE>;
				nvidia,enable-input = <TEGRA_PIN_ENABLE>;
				nvidia,io-high-voltage = <TEGRA_PIN_ENABLE>;
				nvidia,lpdr = <TEGRA_PIN_DISABLE>;
			};

			soc_gpio39_pn1 {
				nvidia,pins = "soc_gpio39_pn1";
				nvidia,function = "rsvd1";
				nvidia,pull = <TEGRA_PIN_PULL_DOWN>;
				nvidia,tristate = <TEGRA_PIN_ENABLE>;
				nvidia,enable-input = <TEGRA_PIN_ENABLE>;
				nvidia,lpdr = <TEGRA_PIN_DISABLE>;
			};

			soc_gpio13_pg0 {
				nvidia,pins = "soc_gpio13_pg0";
				nvidia,function = "rsvd0";
				nvidia,pull = <TEGRA_PIN_PULL_UP>;
				nvidia,tristate = <TEGRA_PIN_ENABLE>;
				nvidia,enable-input = <TEGRA_PIN_ENABLE>;
				nvidia,lpdr = <TEGRA_PIN_DISABLE>;
			};

			soc_gpio14_pg1 {
				nvidia,pins = "soc_gpio14_pg1";
				nvidia,function = "rsvd0";
				nvidia,pull = <TEGRA_PIN_PULL_UP>;
				nvidia,tristate = <TEGRA_PIN_ENABLE>;
				nvidia,enable-input = <TEGRA_PIN_ENABLE>;
				nvidia,lpdr = <TEGRA_PIN_DISABLE>;
			};

			soc_gpio15_pg2 {
				nvidia,pins = "soc_gpio15_pg2";
				nvidia,function = "rsvd0";
				nvidia,pull = <TEGRA_PIN_PULL_UP>;
				nvidia,tristate = <TEGRA_PIN_ENABLE>;
				nvidia,enable-input = <TEGRA_PIN_ENABLE>;
				nvidia,lpdr = <TEGRA_PIN_DISABLE>;
			};

			soc_gpio16_pg3 {
				nvidia,pins = "soc_gpio16_pg3";
				nvidia,function = "rsvd0";
				nvidia,pull = <TEGRA_PIN_PULL_NONE>;
				nvidia,tristate = <TEGRA_PIN_DISABLE>;
				nvidia,enable-input = <TEGRA_PIN_DISABLE>;
				nvidia,lpdr = <TEGRA_PIN_DISABLE>;
			};

			soc_gpio20_pg7 {
				nvidia,pins = "soc_gpio20_pg7";
				nvidia,function = "rsvd0";
				nvidia,pull = <TEGRA_PIN_PULL_UP>;
				nvidia,tristate = <TEGRA_PIN_ENABLE>;
				nvidia,enable-input = <TEGRA_PIN_ENABLE>;
				nvidia,lpdr = <TEGRA_PIN_DISABLE>;
			};

			soc_gpio21_ph0 {
				nvidia,pins = "soc_gpio21_ph0";
				nvidia,function = "rsvd0";
				nvidia,pull = <TEGRA_PIN_PULL_DOWN>;
				nvidia,tristate = <TEGRA_PIN_ENABLE>;
				nvidia,enable-input = <TEGRA_PIN_ENABLE>;
				nvidia,lpdr = <TEGRA_PIN_DISABLE>;
			};

			soc_gpio22_ph1 {
				nvidia,pins = "soc_gpio22_ph1";
				nvidia,function = "rsvd0";
				nvidia,pull = <TEGRA_PIN_PULL_NONE>;
				nvidia,tristate = <TEGRA_PIN_DISABLE>;
				nvidia,enable-input = <TEGRA_PIN_DISABLE>;
				nvidia,lpdr = <TEGRA_PIN_DISABLE>;
			};

			uart4_tx_ph3 {
				nvidia,pins = "uart4_tx_ph3";
				nvidia,function = "rsvd2";
				nvidia,pull = <TEGRA_PIN_PULL_NONE>;
				nvidia,tristate = <TEGRA_PIN_DISABLE>;
				nvidia,enable-input = <TEGRA_PIN_DISABLE>;
				nvidia,lpdr = <TEGRA_PIN_DISABLE>;
			};

			uart4_rx_ph4 {
				nvidia,pins = "uart4_rx_ph4";
				nvidia,function = "rsvd1";
				nvidia,pull = <TEGRA_PIN_PULL_NONE>;
				nvidia,tristate = <TEGRA_PIN_DISABLE>;
				nvidia,enable-input = <TEGRA_PIN_DISABLE>;
				nvidia,lpdr = <TEGRA_PIN_DISABLE>;
			};

			uart4_rts_ph5 {
				nvidia,pins = "uart4_rts_ph5";
				nvidia,function = "rsvd2";
				nvidia,pull = <TEGRA_PIN_PULL_NONE>;
				nvidia,tristate = <TEGRA_PIN_DISABLE>;
				nvidia,enable-input = <TEGRA_PIN_DISABLE>;
				nvidia,lpdr = <TEGRA_PIN_DISABLE>;
			};

			uart4_cts_ph6 {
				nvidia,pins = "uart4_cts_ph6";
				nvidia,function = "rsvd1";
				nvidia,pull = <TEGRA_PIN_PULL_NONE>;
				nvidia,tristate = <TEGRA_PIN_DISABLE>;
				nvidia,enable-input = <TEGRA_PIN_DISABLE>;
				nvidia,lpdr = <TEGRA_PIN_DISABLE>;
			};

			soc_gpio41_ph7 {
				nvidia,pins = "soc_gpio41_ph7";
				nvidia,function = "rsvd2";
				nvidia,pull = <TEGRA_PIN_PULL_DOWN>;
				nvidia,tristate = <TEGRA_PIN_ENABLE>;
				nvidia,enable-input = <TEGRA_PIN_ENABLE>;
				nvidia,lpdr = <TEGRA_PIN_DISABLE>;
			};

			soc_gpio42_pi0 {
				nvidia,pins = "soc_gpio42_pi0";
				nvidia,function = "rsvd2";
				nvidia,pull = <TEGRA_PIN_PULL_DOWN>;
				nvidia,tristate = <TEGRA_PIN_ENABLE>;
				nvidia,enable-input = <TEGRA_PIN_ENABLE>;
				nvidia,lpdr = <TEGRA_PIN_DISABLE>;
			};

			soc_gpio43_pi1 {
				nvidia,pins = "soc_gpio43_pi1";
				nvidia,function = "rsvd2";
				nvidia,pull = <TEGRA_PIN_PULL_DOWN>;
				nvidia,tristate = <TEGRA_PIN_ENABLE>;
				nvidia,enable-input = <TEGRA_PIN_ENABLE>;
				nvidia,lpdr = <TEGRA_PIN_DISABLE>;
			};

			soc_gpio44_pi2 {
				nvidia,pins = "soc_gpio44_pi2";
				nvidia,function = "rsvd2";
				nvidia,pull = <TEGRA_PIN_PULL_DOWN>;
				nvidia,tristate = <TEGRA_PIN_ENABLE>;
				nvidia,enable-input = <TEGRA_PIN_ENABLE>;
				nvidia,lpdr = <TEGRA_PIN_DISABLE>;
			};

			cpu_pwr_req_pi5 {
				nvidia,pins = "cpu_pwr_req_pi5";
				nvidia,function = "rsvd0";
				nvidia,pull = <TEGRA_PIN_PULL_NONE>;
				nvidia,tristate = <TEGRA_PIN_DISABLE>;
				nvidia,enable-input = <TEGRA_PIN_DISABLE>;
				nvidia,lpdr = <TEGRA_PIN_DISABLE>;
			};

			spi5_sck_pac0 {
				nvidia,pins = "spi5_sck_pac0";
				nvidia,function = "rsvd3";
				nvidia,pull = <TEGRA_PIN_PULL_NONE>;
				nvidia,tristate = <TEGRA_PIN_DISABLE>;
				nvidia,enable-input = <TEGRA_PIN_DISABLE>;
				nvidia,lpdr = <TEGRA_PIN_DISABLE>;
			};

			spi5_miso_pac1 {
				nvidia,pins = "spi5_miso_pac1";
				nvidia,function = "rsvd3";
				nvidia,pull = <TEGRA_PIN_PULL_NONE>;
				nvidia,tristate = <TEGRA_PIN_DISABLE>;
				nvidia,enable-input = <TEGRA_PIN_DISABLE>;
				nvidia,lpdr = <TEGRA_PIN_DISABLE>;
			};

			spi5_mosi_pac2 {
				nvidia,pins = "spi5_mosi_pac2";
				nvidia,function = "rsvd3";
				nvidia,pull = <TEGRA_PIN_PULL_NONE>;
				nvidia,tristate = <TEGRA_PIN_DISABLE>;
				nvidia,enable-input = <TEGRA_PIN_DISABLE>;
				nvidia,lpdr = <TEGRA_PIN_DISABLE>;
			};

			spi5_cs0_pac3 {
				nvidia,pins = "spi5_cs0_pac3";
				nvidia,function = "rsvd3";
				nvidia,pull = <TEGRA_PIN_PULL_DOWN>;
				nvidia,tristate = <TEGRA_PIN_ENABLE>;
				nvidia,enable-input = <TEGRA_PIN_ENABLE>;
				nvidia,lpdr = <TEGRA_PIN_DISABLE>;
			};

			soc_gpio57_pac4 {
				nvidia,pins = "soc_gpio57_pac4";
				nvidia,function = "rsvd0";
				nvidia,pull = <TEGRA_PIN_PULL_DOWN>;
				nvidia,tristate = <TEGRA_PIN_ENABLE>;
				nvidia,enable-input = <TEGRA_PIN_ENABLE>;
				nvidia,lpdr = <TEGRA_PIN_DISABLE>;
			};

			soc_gpio58_pac5 {
				nvidia,pins = "soc_gpio58_pac5";
				nvidia,function = "rsvd0";
				nvidia,pull = <TEGRA_PIN_PULL_UP>;
				nvidia,tristate = <TEGRA_PIN_ENABLE>;
				nvidia,enable-input = <TEGRA_PIN_ENABLE>;
				nvidia,lpdr = <TEGRA_PIN_DISABLE>;
			};

			soc_gpio60_pac7 {
				nvidia,pins = "soc_gpio60_pac7";
				nvidia,function = "rsvd0";
				nvidia,pull = <TEGRA_PIN_PULL_NONE>;
				nvidia,tristate = <TEGRA_PIN_DISABLE>;
				nvidia,enable-input = <TEGRA_PIN_DISABLE>;
				nvidia,lpdr = <TEGRA_PIN_DISABLE>;
			};

			ufs0_ref_clk_pae0 {
				nvidia,pins = "ufs0_ref_clk_pae0";
				nvidia,function = "rsvd1";
				nvidia,pull = <TEGRA_PIN_PULL_UP>;
				nvidia,tristate = <TEGRA_PIN_ENABLE>;
				nvidia,enable-input = <TEGRA_PIN_ENABLE>;
			};

			ufs0_rst_n_pae1 {
				nvidia,pins = "ufs0_rst_n_pae1";
				nvidia,function = "rsvd1";
				nvidia,pull = <TEGRA_PIN_PULL_UP>;
				nvidia,tristate = <TEGRA_PIN_ENABLE>;
				nvidia,enable-input = <TEGRA_PIN_ENABLE>;
			};

			pex_l0_clkreq_n_pk0 {
				nvidia,pins = "pex_l0_clkreq_n_pk0";
				nvidia,function = "rsvd1";
				nvidia,pull = <TEGRA_PIN_PULL_NONE>;
				nvidia,tristate = <TEGRA_PIN_ENABLE>;
				nvidia,enable-input = <TEGRA_PIN_ENABLE>;
				nvidia,io-high-voltage = <TEGRA_PIN_ENABLE>;
				nvidia,lpdr = <TEGRA_PIN_DISABLE>;
			};

			pex_l0_rst_n_pk1 {
				nvidia,pins = "pex_l0_rst_n_pk1";
				nvidia,function = "rsvd1";
				nvidia,pull = <TEGRA_PIN_PULL_NONE>;
				nvidia,tristate = <TEGRA_PIN_ENABLE>;
				nvidia,enable-input = <TEGRA_PIN_ENABLE>;
				nvidia,io-high-voltage = <TEGRA_PIN_ENABLE>;
				nvidia,lpdr = <TEGRA_PIN_DISABLE>;
			};

			pex_l2_clkreq_n_pk4 {
				nvidia,pins = "pex_l2_clkreq_n_pk4";
				nvidia,function = "rsvd1";
				nvidia,pull = <TEGRA_PIN_PULL_NONE>;
				nvidia,tristate = <TEGRA_PIN_ENABLE>;
				nvidia,enable-input = <TEGRA_PIN_DISABLE>;
				nvidia,io-high-voltage = <TEGRA_PIN_DISABLE>;
				nvidia,lpdr = <TEGRA_PIN_DISABLE>;
			};

			pex_l2_rst_n_pk5 {
				nvidia,pins = "pex_l2_rst_n_pk5";
				nvidia,function = "rsvd1";
				nvidia,pull = <TEGRA_PIN_PULL_NONE>;
				nvidia,tristate = <TEGRA_PIN_DISABLE>;
				nvidia,enable-input = <TEGRA_PIN_DISABLE>;
				nvidia,io-high-voltage = <TEGRA_PIN_DISABLE>;
				nvidia,lpdr = <TEGRA_PIN_DISABLE>;
			};

			pex_l3_clkreq_n_pk6 {
				nvidia,pins = "pex_l3_clkreq_n_pk6";
				nvidia,function = "rsvd1";
				nvidia,pull = <TEGRA_PIN_PULL_NONE>;
				nvidia,tristate = <TEGRA_PIN_ENABLE>;
				nvidia,enable-input = <TEGRA_PIN_ENABLE>;
				nvidia,io-high-voltage = <TEGRA_PIN_ENABLE>;
				nvidia,lpdr = <TEGRA_PIN_DISABLE>;
			};

			pex_l3_rst_n_pk7 {
				nvidia,pins = "pex_l3_rst_n_pk7";
				nvidia,function = "rsvd1";
				nvidia,pull = <TEGRA_PIN_PULL_NONE>;
				nvidia,tristate = <TEGRA_PIN_ENABLE>;
				nvidia,enable-input = <TEGRA_PIN_ENABLE>;
				nvidia,io-high-voltage = <TEGRA_PIN_ENABLE>;
				nvidia,lpdr = <TEGRA_PIN_DISABLE>;
			};

			pex_wake_n_pl2 {
				nvidia,pins = "pex_wake_n_pl2";
				nvidia,function = "rsvd0";
				nvidia,pull = <TEGRA_PIN_PULL_NONE>;
				nvidia,tristate = <TEGRA_PIN_ENABLE>;
				nvidia,enable-input = <TEGRA_PIN_ENABLE>;
				nvidia,io-high-voltage = <TEGRA_PIN_ENABLE>;
				nvidia,lpdr = <TEGRA_PIN_DISABLE>;
			};

			soc_gpio34_pl3 {
				nvidia,pins = "soc_gpio34_pl3";
				nvidia,function = "rsvd1";
				nvidia,pull = <TEGRA_PIN_PULL_DOWN>;
				nvidia,tristate = <TEGRA_PIN_ENABLE>;
				nvidia,enable-input = <TEGRA_PIN_ENABLE>;
				nvidia,io-high-voltage = <TEGRA_PIN_ENABLE>;
				nvidia,lpdr = <TEGRA_PIN_DISABLE>;
			};

			pex_l7_clkreq_n_pag0 {
				nvidia,pins = "pex_l7_clkreq_n_pag0";
				nvidia,function = "rsvd1";
				nvidia,pull = <TEGRA_PIN_PULL_NONE>;
				nvidia,tristate = <TEGRA_PIN_ENABLE>;
				nvidia,enable-input = <TEGRA_PIN_ENABLE>;
				nvidia,io-high-voltage = <TEGRA_PIN_ENABLE>;
				nvidia,lpdr = <TEGRA_PIN_DISABLE>;
			};

			pex_l7_rst_n_pag1 {
				nvidia,pins = "pex_l7_rst_n_pag1";
				nvidia,function = "rsvd1";
				nvidia,pull = <TEGRA_PIN_PULL_NONE>;
				nvidia,tristate = <TEGRA_PIN_ENABLE>;
				nvidia,enable-input = <TEGRA_PIN_ENABLE>;
				nvidia,io-high-voltage = <TEGRA_PIN_ENABLE>;
				nvidia,lpdr = <TEGRA_PIN_DISABLE>;
			};

			pex_l8_clkreq_n_pag2 {
				nvidia,pins = "pex_l8_clkreq_n_pag2";
				nvidia,function = "rsvd1";
				nvidia,pull = <TEGRA_PIN_PULL_NONE>;
				nvidia,tristate = <TEGRA_PIN_ENABLE>;
				nvidia,enable-input = <TEGRA_PIN_ENABLE>;
				nvidia,io-high-voltage = <TEGRA_PIN_ENABLE>;
				nvidia,lpdr = <TEGRA_PIN_DISABLE>;
			};

			pex_l8_rst_n_pag3 {
				nvidia,pins = "pex_l8_rst_n_pag3";
				nvidia,function = "rsvd1";
				nvidia,pull = <TEGRA_PIN_PULL_NONE>;
				nvidia,tristate = <TEGRA_PIN_ENABLE>;
				nvidia,enable-input = <TEGRA_PIN_ENABLE>;
				nvidia,io-high-voltage = <TEGRA_PIN_ENABLE>;
				nvidia,lpdr = <TEGRA_PIN_DISABLE>;
			};

			pex_l9_clkreq_n_pag4 {
				nvidia,pins = "pex_l9_clkreq_n_pag4";
				nvidia,function = "rsvd1";
				nvidia,pull = <TEGRA_PIN_PULL_NONE>;
				nvidia,tristate = <TEGRA_PIN_ENABLE>;
				nvidia,enable-input = <TEGRA_PIN_DISABLE>;
				nvidia,io-high-voltage = <TEGRA_PIN_DISABLE>;
				nvidia,lpdr = <TEGRA_PIN_DISABLE>;
			};

			pex_l9_rst_n_pag5 {
				nvidia,pins = "pex_l9_rst_n_pag5";
				nvidia,function = "rsvd1";
				nvidia,pull = <TEGRA_PIN_PULL_NONE>;
				nvidia,tristate = <TEGRA_PIN_ENABLE>;
				nvidia,enable-input = <TEGRA_PIN_DISABLE>;
				nvidia,io-high-voltage = <TEGRA_PIN_DISABLE>;
				nvidia,lpdr = <TEGRA_PIN_DISABLE>;
			};

			pex_l10_clkreq_n_pag6 {
				nvidia,pins = "pex_l10_clkreq_n_pag6";
				nvidia,function = "rsvd1";
				nvidia,pull = <TEGRA_PIN_PULL_NONE>;
				nvidia,tristate = <TEGRA_PIN_ENABLE>;
				nvidia,enable-input = <TEGRA_PIN_ENABLE>;
				nvidia,io-high-voltage = <TEGRA_PIN_ENABLE>;
				nvidia,lpdr = <TEGRA_PIN_DISABLE>;
			};

			pex_l10_rst_n_pag7 {
				nvidia,pins = "pex_l10_rst_n_pag7";
				nvidia,function = "rsvd1";
				nvidia,pull = <TEGRA_PIN_PULL_NONE>;
				nvidia,tristate = <TEGRA_PIN_ENABLE>;
				nvidia,enable-input = <TEGRA_PIN_ENABLE>;
				nvidia,io-high-voltage = <TEGRA_PIN_ENABLE>;
				nvidia,lpdr = <TEGRA_PIN_DISABLE>;
			};

			dap6_sclk_pa0 {
				nvidia,pins = "dap6_sclk_pa0";
				nvidia,function = "rsvd1";
				nvidia,pull = <TEGRA_PIN_PULL_NONE>;
				nvidia,tristate = <TEGRA_PIN_DISABLE>;
				nvidia,enable-input = <TEGRA_PIN_DISABLE>;
				nvidia,lpdr = <TEGRA_PIN_DISABLE>;
			};

			dap6_dout_pa1 {
				nvidia,pins = "dap6_dout_pa1";
				nvidia,function = "rsvd1";
				nvidia,pull = <TEGRA_PIN_PULL_NONE>;
				nvidia,tristate = <TEGRA_PIN_DISABLE>;
				nvidia,enable-input = <TEGRA_PIN_DISABLE>;
				nvidia,lpdr = <TEGRA_PIN_DISABLE>;
			};

			dap6_din_pa2 {
				nvidia,pins = "dap6_din_pa2";
				nvidia,function = "rsvd1";
				nvidia,pull = <TEGRA_PIN_PULL_NONE>;
				nvidia,tristate = <TEGRA_PIN_DISABLE>;
				nvidia,enable-input = <TEGRA_PIN_DISABLE>;
				nvidia,lpdr = <TEGRA_PIN_DISABLE>;
			};

			dap6_fs_pa3 {
				nvidia,pins = "dap6_fs_pa3";
				nvidia,function = "rsvd1";
				nvidia,pull = <TEGRA_PIN_PULL_NONE>;
				nvidia,tristate = <TEGRA_PIN_DISABLE>;
				nvidia,enable-input = <TEGRA_PIN_DISABLE>;
				nvidia,lpdr = <TEGRA_PIN_DISABLE>;
			};

			pex_l6_clkreq_n_paf2 {
				nvidia,pins = "pex_l6_clkreq_n_paf2";
				nvidia,function = "rsvd1";
				nvidia,pull = <TEGRA_PIN_PULL_NONE>;
				nvidia,tristate = <TEGRA_PIN_ENABLE>;
				nvidia,enable-input = <TEGRA_PIN_ENABLE>;
				nvidia,io-high-voltage = <TEGRA_PIN_ENABLE>;
				nvidia,lpdr = <TEGRA_PIN_DISABLE>;
			};

			pex_l6_rst_n_paf3 {
				nvidia,pins = "pex_l6_rst_n_paf3";
				nvidia,function = "rsvd1";
				nvidia,pull = <TEGRA_PIN_PULL_NONE>;
				nvidia,tristate = <TEGRA_PIN_ENABLE>;
				nvidia,enable-input = <TEGRA_PIN_ENABLE>;
				nvidia,io-high-voltage = <TEGRA_PIN_ENABLE>;
				nvidia,lpdr = <TEGRA_PIN_DISABLE>;
			};
		};

		pinmux_unused_lowpower: unused_lowpower {
			sce_error_pee0 {
				nvidia,pins = "sce_error_pee0";
				nvidia,function = "rsvd1";
				nvidia,pull = <TEGRA_PIN_PULL_DOWN>;
				nvidia,tristate = <TEGRA_PIN_ENABLE>;
				nvidia,enable-input = <TEGRA_PIN_DISABLE>;
				nvidia,io-high-voltage = <TEGRA_PIN_DISABLE>;
				nvidia,lpdr = <TEGRA_PIN_DISABLE>;
			};

			vcomp_alert_pee1 {
				nvidia,pins = "vcomp_alert_pee1";
				nvidia,function = "rsvd1";
				nvidia,pull = <TEGRA_PIN_PULL_DOWN>;
				nvidia,tristate = <TEGRA_PIN_ENABLE>;
				nvidia,enable-input = <TEGRA_PIN_DISABLE>;
				nvidia,io-high-voltage = <TEGRA_PIN_DISABLE>;
				nvidia,lpdr = <TEGRA_PIN_DISABLE>;
			};

			bootv_ctl_n_pee7 {
				nvidia,pins = "bootv_ctl_n_pee7";
				nvidia,function = "rsvd0";
				nvidia,pull = <TEGRA_PIN_PULL_DOWN>;
				nvidia,tristate = <TEGRA_PIN_ENABLE>;
				nvidia,enable-input = <TEGRA_PIN_DISABLE>;
				nvidia,io-high-voltage = <TEGRA_PIN_DISABLE>;
				nvidia,lpdr = <TEGRA_PIN_DISABLE>;
			};

			can0_en_paa5 {
				nvidia,pins = "can0_en_paa5";
				nvidia,function = "rsvd0";
				nvidia,pull = <TEGRA_PIN_PULL_DOWN>;
				nvidia,tristate = <TEGRA_PIN_ENABLE>;
				nvidia,enable-input = <TEGRA_PIN_DISABLE>;
			};

			soc_gpio49_paa6 {
				nvidia,pins = "soc_gpio49_paa6";
				nvidia,function = "rsvd0";
				nvidia,pull = <TEGRA_PIN_PULL_DOWN>;
				nvidia,tristate = <TEGRA_PIN_ENABLE>;
				nvidia,enable-input = <TEGRA_PIN_DISABLE>;
			};

			soc_gpio30_pq3 {
				nvidia,pins = "soc_gpio30_pq3";
				nvidia,function = "rsvd0";
				nvidia,pull = <TEGRA_PIN_PULL_DOWN>;
				nvidia,tristate = <TEGRA_PIN_ENABLE>;
				nvidia,enable-input = <TEGRA_PIN_DISABLE>;
				nvidia,io-high-voltage = <TEGRA_PIN_DISABLE>;
				nvidia,lpdr = <TEGRA_PIN_DISABLE>;
			};

			dp_aux_ch2_p_pn5 {
				nvidia,pins = "dp_aux_ch2_p_pn5";
				nvidia,function = "rsvd1";
				nvidia,pull = <TEGRA_PIN_PULL_DOWN>;
				nvidia,tristate = <TEGRA_PIN_ENABLE>;
				nvidia,enable-input = <TEGRA_PIN_DISABLE>;
				nvidia,io-high-voltage = <TEGRA_PIN_DISABLE>;
				nvidia,lpdr = <TEGRA_PIN_DISABLE>;
			};

			dp_aux_ch2_n_pn6 {
				nvidia,pins = "dp_aux_ch2_n_pn6";
				nvidia,function = "rsvd1";
				nvidia,pull = <TEGRA_PIN_PULL_DOWN>;
				nvidia,tristate = <TEGRA_PIN_ENABLE>;
				nvidia,enable-input = <TEGRA_PIN_DISABLE>;
				nvidia,io-high-voltage = <TEGRA_PIN_DISABLE>;
				nvidia,lpdr = <TEGRA_PIN_DISABLE>;
			};

			soc_gpio17_pg4 {
				nvidia,pins = "soc_gpio17_pg4";
				nvidia,function = "rsvd0";
				nvidia,pull = <TEGRA_PIN_PULL_DOWN>;
				nvidia,tristate = <TEGRA_PIN_ENABLE>;
				nvidia,enable-input = <TEGRA_PIN_DISABLE>;
				nvidia,lpdr = <TEGRA_PIN_DISABLE>;
			};

			soc_gpio18_pg5 {
				nvidia,pins = "soc_gpio18_pg5";
				nvidia,function = "rsvd0";
				nvidia,pull = <TEGRA_PIN_PULL_DOWN>;
				nvidia,tristate = <TEGRA_PIN_ENABLE>;
				nvidia,enable-input = <TEGRA_PIN_DISABLE>;
				nvidia,lpdr = <TEGRA_PIN_DISABLE>;
			};

			soc_gpio06_ph2 {
				nvidia,pins = "soc_gpio06_ph2";
				nvidia,function = "rsvd0";
				nvidia,pull = <TEGRA_PIN_PULL_DOWN>;
				nvidia,tristate = <TEGRA_PIN_ENABLE>;
				nvidia,enable-input = <TEGRA_PIN_DISABLE>;
				nvidia,lpdr = <TEGRA_PIN_DISABLE>;
			};

			qspi1_sck_pc6 {
				nvidia,pins = "qspi1_sck_pc6";
				nvidia,function = "rsvd1";
				nvidia,pull = <TEGRA_PIN_PULL_DOWN>;
				nvidia,tristate = <TEGRA_PIN_ENABLE>;
				nvidia,enable-input = <TEGRA_PIN_DISABLE>;
				nvidia,loopback = <TEGRA_PIN_ENABLE>;
			};

			qspi1_cs_n_pc7 {
				nvidia,pins = "qspi1_cs_n_pc7";
				nvidia,function = "rsvd1";
				nvidia,pull = <TEGRA_PIN_PULL_DOWN>;
				nvidia,tristate = <TEGRA_PIN_ENABLE>;
				nvidia,enable-input = <TEGRA_PIN_DISABLE>;
			};

			qspi1_io0_pd0 {
				nvidia,pins = "qspi1_io0_pd0";
				nvidia,function = "rsvd1";
				nvidia,pull = <TEGRA_PIN_PULL_DOWN>;
				nvidia,tristate = <TEGRA_PIN_ENABLE>;
				nvidia,enable-input = <TEGRA_PIN_DISABLE>;
			};

			qspi1_io1_pd1 {
				nvidia,pins = "qspi1_io1_pd1";
				nvidia,function = "rsvd1";
				nvidia,pull = <TEGRA_PIN_PULL_DOWN>;
				nvidia,tristate = <TEGRA_PIN_ENABLE>;
				nvidia,enable-input = <TEGRA_PIN_DISABLE>;
			};

			qspi1_io2_pd2 {
				nvidia,pins = "qspi1_io2_pd2";
				nvidia,function = "rsvd1";
				nvidia,pull = <TEGRA_PIN_PULL_DOWN>;
				nvidia,tristate = <TEGRA_PIN_ENABLE>;
				nvidia,enable-input = <TEGRA_PIN_DISABLE>;
			};

			qspi1_io3_pd3 {
				nvidia,pins = "qspi1_io3_pd3";
				nvidia,function = "rsvd1";
				nvidia,pull = <TEGRA_PIN_PULL_DOWN>;
				nvidia,tristate = <TEGRA_PIN_ENABLE>;
				nvidia,enable-input = <TEGRA_PIN_DISABLE>;
			};

			eqos_txc_pe0 {
				nvidia,pins = "eqos_txc_pe0";
				nvidia,function = "rsvd1";
				nvidia,pull = <TEGRA_PIN_PULL_DOWN>;
				nvidia,tristate = <TEGRA_PIN_ENABLE>;
				nvidia,enable-input = <TEGRA_PIN_DISABLE>;
			};

			eqos_td0_pe1 {
				nvidia,pins = "eqos_td0_pe1";
				nvidia,function = "rsvd1";
				nvidia,pull = <TEGRA_PIN_PULL_DOWN>;
				nvidia,tristate = <TEGRA_PIN_ENABLE>;
				nvidia,enable-input = <TEGRA_PIN_DISABLE>;
			};

			eqos_td1_pe2 {
				nvidia,pins = "eqos_td1_pe2";
				nvidia,function = "rsvd1";
				nvidia,pull = <TEGRA_PIN_PULL_DOWN>;
				nvidia,tristate = <TEGRA_PIN_ENABLE>;
				nvidia,enable-input = <TEGRA_PIN_DISABLE>;
			};

			eqos_td2_pe3 {
				nvidia,pins = "eqos_td2_pe3";
				nvidia,function = "rsvd1";
				nvidia,pull = <TEGRA_PIN_PULL_DOWN>;
				nvidia,tristate = <TEGRA_PIN_ENABLE>;
				nvidia,enable-input = <TEGRA_PIN_DISABLE>;
			};

			eqos_td3_pe4 {
				nvidia,pins = "eqos_td3_pe4";
				nvidia,function = "rsvd1";
				nvidia,pull = <TEGRA_PIN_PULL_DOWN>;
				nvidia,tristate = <TEGRA_PIN_ENABLE>;
				nvidia,enable-input = <TEGRA_PIN_DISABLE>;
			};

			eqos_tx_ctl_pe5 {
				nvidia,pins = "eqos_tx_ctl_pe5";
				nvidia,function = "rsvd1";
				nvidia,pull = <TEGRA_PIN_PULL_DOWN>;
				nvidia,tristate = <TEGRA_PIN_ENABLE>;
				nvidia,enable-input = <TEGRA_PIN_DISABLE>;
			};

			eqos_rd0_pe6 {
				nvidia,pins = "eqos_rd0_pe6";
				nvidia,function = "rsvd1";
				nvidia,pull = <TEGRA_PIN_PULL_DOWN>;
				nvidia,tristate = <TEGRA_PIN_ENABLE>;
				nvidia,enable-input = <TEGRA_PIN_DISABLE>;
			};

			eqos_rd1_pe7 {
				nvidia,pins = "eqos_rd1_pe7";
				nvidia,function = "rsvd1";
				nvidia,pull = <TEGRA_PIN_PULL_DOWN>;
				nvidia,tristate = <TEGRA_PIN_ENABLE>;
				nvidia,enable-input = <TEGRA_PIN_DISABLE>;
			};

			eqos_rd2_pf0 {
				nvidia,pins = "eqos_rd2_pf0";
				nvidia,function = "rsvd1";
				nvidia,pull = <TEGRA_PIN_PULL_DOWN>;
				nvidia,tristate = <TEGRA_PIN_ENABLE>;
				nvidia,enable-input = <TEGRA_PIN_DISABLE>;
			};

			eqos_rd3_pf1 {
				nvidia,pins = "eqos_rd3_pf1";
				nvidia,function = "rsvd1";
				nvidia,pull = <TEGRA_PIN_PULL_DOWN>;
				nvidia,tristate = <TEGRA_PIN_ENABLE>;
				nvidia,enable-input = <TEGRA_PIN_DISABLE>;
			};

			eqos_rx_ctl_pf2 {
				nvidia,pins = "eqos_rx_ctl_pf2";
				nvidia,function = "rsvd1";
				nvidia,pull = <TEGRA_PIN_PULL_DOWN>;
				nvidia,tristate = <TEGRA_PIN_ENABLE>;
				nvidia,enable-input = <TEGRA_PIN_DISABLE>;
			};

			eqos_rxc_pf3 {
				nvidia,pins = "eqos_rxc_pf3";
				nvidia,function = "rsvd1";
				nvidia,pull = <TEGRA_PIN_PULL_DOWN>;
				nvidia,tristate = <TEGRA_PIN_ENABLE>;
				nvidia,enable-input = <TEGRA_PIN_DISABLE>;
			};

			eqos_sma_mdio_pf4 {
				nvidia,pins = "eqos_sma_mdio_pf4";
				nvidia,function = "rsvd1";
				nvidia,pull = <TEGRA_PIN_PULL_DOWN>;
				nvidia,tristate = <TEGRA_PIN_ENABLE>;
				nvidia,enable-input = <TEGRA_PIN_DISABLE>;
			};

			eqos_sma_mdc_pf5 {
				nvidia,pins = "eqos_sma_mdc_pf5";
				nvidia,function = "rsvd1";
				nvidia,pull = <TEGRA_PIN_PULL_DOWN>;
				nvidia,tristate = <TEGRA_PIN_ENABLE>;
				nvidia,enable-input = <TEGRA_PIN_DISABLE>;
			};

			can2_dout_ps0 {
				nvidia,pins = "can2_dout_ps0";
				nvidia,function = "rsvd1";
				nvidia,pull = <TEGRA_PIN_PULL_DOWN>;
				nvidia,tristate = <TEGRA_PIN_ENABLE>;
				nvidia,enable-input = <TEGRA_PIN_DISABLE>;
			};

			can2_din_ps1 {
				nvidia,pins = "can2_din_ps1";
				nvidia,function = "rsvd1";
				nvidia,pull = <TEGRA_PIN_PULL_DOWN>;
				nvidia,tristate = <TEGRA_PIN_ENABLE>;
				nvidia,enable-input = <TEGRA_PIN_DISABLE>;
			};

			can2_stb_ps2 {
				nvidia,pins = "can2_stb_ps2";
				nvidia,function = "rsvd0";
				nvidia,pull = <TEGRA_PIN_PULL_DOWN>;
				nvidia,tristate = <TEGRA_PIN_ENABLE>;
				nvidia,enable-input = <TEGRA_PIN_DISABLE>;
			};

			can2_en_ps3 {
				nvidia,pins = "can2_en_ps3";
				nvidia,function = "rsvd0";
				nvidia,pull = <TEGRA_PIN_PULL_DOWN>;
				nvidia,tristate = <TEGRA_PIN_ENABLE>;
				nvidia,enable-input = <TEGRA_PIN_DISABLE>;
			};

			can2_err_ps4 {
				nvidia,pins = "can2_err_ps4";
				nvidia,function = "rsvd0";
				nvidia,pull = <TEGRA_PIN_PULL_DOWN>;
				nvidia,tristate = <TEGRA_PIN_ENABLE>;
				nvidia,enable-input = <TEGRA_PIN_DISABLE>;
			};

			can3_dout_ps5 {
				nvidia,pins = "can3_dout_ps5";
				nvidia,function = "rsvd1";
				nvidia,pull = <TEGRA_PIN_PULL_DOWN>;
				nvidia,tristate = <TEGRA_PIN_ENABLE>;
				nvidia,enable-input = <TEGRA_PIN_DISABLE>;
			};

			can3_din_ps6 {
				nvidia,pins = "can3_din_ps6";
				nvidia,function = "rsvd1";
				nvidia,pull = <TEGRA_PIN_PULL_DOWN>;
				nvidia,tristate = <TEGRA_PIN_ENABLE>;
				nvidia,enable-input = <TEGRA_PIN_DISABLE>;
			};

			can3_stb_ps7 {
				nvidia,pins = "can3_stb_ps7";
				nvidia,function = "rsvd0";
				nvidia,pull = <TEGRA_PIN_PULL_DOWN>;
				nvidia,tristate = <TEGRA_PIN_ENABLE>;
				nvidia,enable-input = <TEGRA_PIN_DISABLE>;
			};

			can3_en_pt0 {
				nvidia,pins = "can3_en_pt0";
				nvidia,function = "rsvd0";
				nvidia,pull = <TEGRA_PIN_PULL_DOWN>;
				nvidia,tristate = <TEGRA_PIN_ENABLE>;
				nvidia,enable-input = <TEGRA_PIN_DISABLE>;
			};

			can3_err_pt1 {
				nvidia,pins = "can3_err_pt1";
				nvidia,function = "rsvd0";
				nvidia,pull = <TEGRA_PIN_PULL_DOWN>;
				nvidia,tristate = <TEGRA_PIN_ENABLE>;
				nvidia,enable-input = <TEGRA_PIN_DISABLE>;
			};

			soc_error_pu0 {
				nvidia,pins = "soc_error_pu0";
				nvidia,function = "rsvd1";
				nvidia,pull = <TEGRA_PIN_PULL_DOWN>;
				nvidia,tristate = <TEGRA_PIN_ENABLE>;
				nvidia,enable-input = <TEGRA_PIN_DISABLE>;
				nvidia,io-high-voltage = <TEGRA_PIN_DISABLE>;
				nvidia,lpdr = <TEGRA_PIN_DISABLE>;
			};

			uart7_tx_pu1 {
				nvidia,pins = "uart7_tx_pu1";
				nvidia,function = "rsvd1";
				nvidia,pull = <TEGRA_PIN_PULL_DOWN>;
				nvidia,tristate = <TEGRA_PIN_ENABLE>;
				nvidia,enable-input = <TEGRA_PIN_DISABLE>;
				nvidia,io-high-voltage = <TEGRA_PIN_DISABLE>;
				nvidia,lpdr = <TEGRA_PIN_DISABLE>;
			};

			uart7_rx_pu2 {
				nvidia,pins = "uart7_rx_pu2";
				nvidia,function = "rsvd1";
				nvidia,pull = <TEGRA_PIN_PULL_DOWN>;
				nvidia,tristate = <TEGRA_PIN_ENABLE>;
				nvidia,enable-input = <TEGRA_PIN_DISABLE>;
				nvidia,io-high-voltage = <TEGRA_PIN_DISABLE>;
				nvidia,lpdr = <TEGRA_PIN_DISABLE>;
			};

			spi7_sck_pu3 {
				nvidia,pins = "spi7_sck_pu3";
				nvidia,function = "rsvd1";
				nvidia,pull = <TEGRA_PIN_PULL_DOWN>;
				nvidia,tristate = <TEGRA_PIN_ENABLE>;
				nvidia,enable-input = <TEGRA_PIN_DISABLE>;
				nvidia,io-high-voltage = <TEGRA_PIN_DISABLE>;
				nvidia,lpdr = <TEGRA_PIN_DISABLE>;
			};

			spi7_miso_pu4 {
				nvidia,pins = "spi7_miso_pu4";
				nvidia,function = "rsvd1";
				nvidia,pull = <TEGRA_PIN_PULL_DOWN>;
				nvidia,tristate = <TEGRA_PIN_ENABLE>;
				nvidia,enable-input = <TEGRA_PIN_DISABLE>;
				nvidia,io-high-voltage = <TEGRA_PIN_DISABLE>;
				nvidia,lpdr = <TEGRA_PIN_DISABLE>;
			};

			spi7_mosi_pu5 {
				nvidia,pins = "spi7_mosi_pu5";
				nvidia,function = "rsvd1";
				nvidia,pull = <TEGRA_PIN_PULL_DOWN>;
				nvidia,tristate = <TEGRA_PIN_ENABLE>;
				nvidia,enable-input = <TEGRA_PIN_DISABLE>;
				nvidia,io-high-voltage = <TEGRA_PIN_DISABLE>;
				nvidia,lpdr = <TEGRA_PIN_DISABLE>;
			};

			spi7_cs0_pu6 {
				nvidia,pins = "spi7_cs0_pu6";
				nvidia,function = "rsvd1";
				nvidia,pull = <TEGRA_PIN_PULL_DOWN>;
				nvidia,tristate = <TEGRA_PIN_ENABLE>;
				nvidia,enable-input = <TEGRA_PIN_DISABLE>;
				nvidia,io-high-voltage = <TEGRA_PIN_DISABLE>;
				nvidia,lpdr = <TEGRA_PIN_DISABLE>;
			};

			soc_gpio51_pu7 {
				nvidia,pins = "soc_gpio51_pu7";
				nvidia,function = "rsvd0";
				nvidia,pull = <TEGRA_PIN_PULL_DOWN>;
				nvidia,tristate = <TEGRA_PIN_ENABLE>;
				nvidia,enable-input = <TEGRA_PIN_DISABLE>;
				nvidia,io-high-voltage = <TEGRA_PIN_DISABLE>;
				nvidia,lpdr = <TEGRA_PIN_DISABLE>;
			};

			soc_gpio52_pv0 {
				nvidia,pins = "soc_gpio52_pv0";
				nvidia,function = "rsvd0";
				nvidia,pull = <TEGRA_PIN_PULL_DOWN>;
				nvidia,tristate = <TEGRA_PIN_ENABLE>;
				nvidia,enable-input = <TEGRA_PIN_DISABLE>;
				nvidia,io-high-voltage = <TEGRA_PIN_DISABLE>;
				nvidia,lpdr = <TEGRA_PIN_DISABLE>;
			};

			soc_gpio61_pw0 {
				nvidia,pins = "soc_gpio61_pw0";
				nvidia,function = "rsvd3";
				nvidia,pull = <TEGRA_PIN_PULL_DOWN>;
				nvidia,tristate = <TEGRA_PIN_ENABLE>;
				nvidia,enable-input = <TEGRA_PIN_DISABLE>;
				nvidia,io-high-voltage = <TEGRA_PIN_DISABLE>;
				nvidia,lpdr = <TEGRA_PIN_DISABLE>;
			};

			soc_gpio62_pw1 {
				nvidia,pins = "soc_gpio62_pw1";
				nvidia,function = "rsvd3";
				nvidia,pull = <TEGRA_PIN_PULL_DOWN>;
				nvidia,tristate = <TEGRA_PIN_ENABLE>;
				nvidia,enable-input = <TEGRA_PIN_DISABLE>;
				nvidia,io-high-voltage = <TEGRA_PIN_DISABLE>;
				nvidia,lpdr = <TEGRA_PIN_DISABLE>;
			};
		};

		drive_default: drive {
		};
	};
};
